AUTOSAR XML (schema 3.1.2)
package /Components/SWC_ThMgt
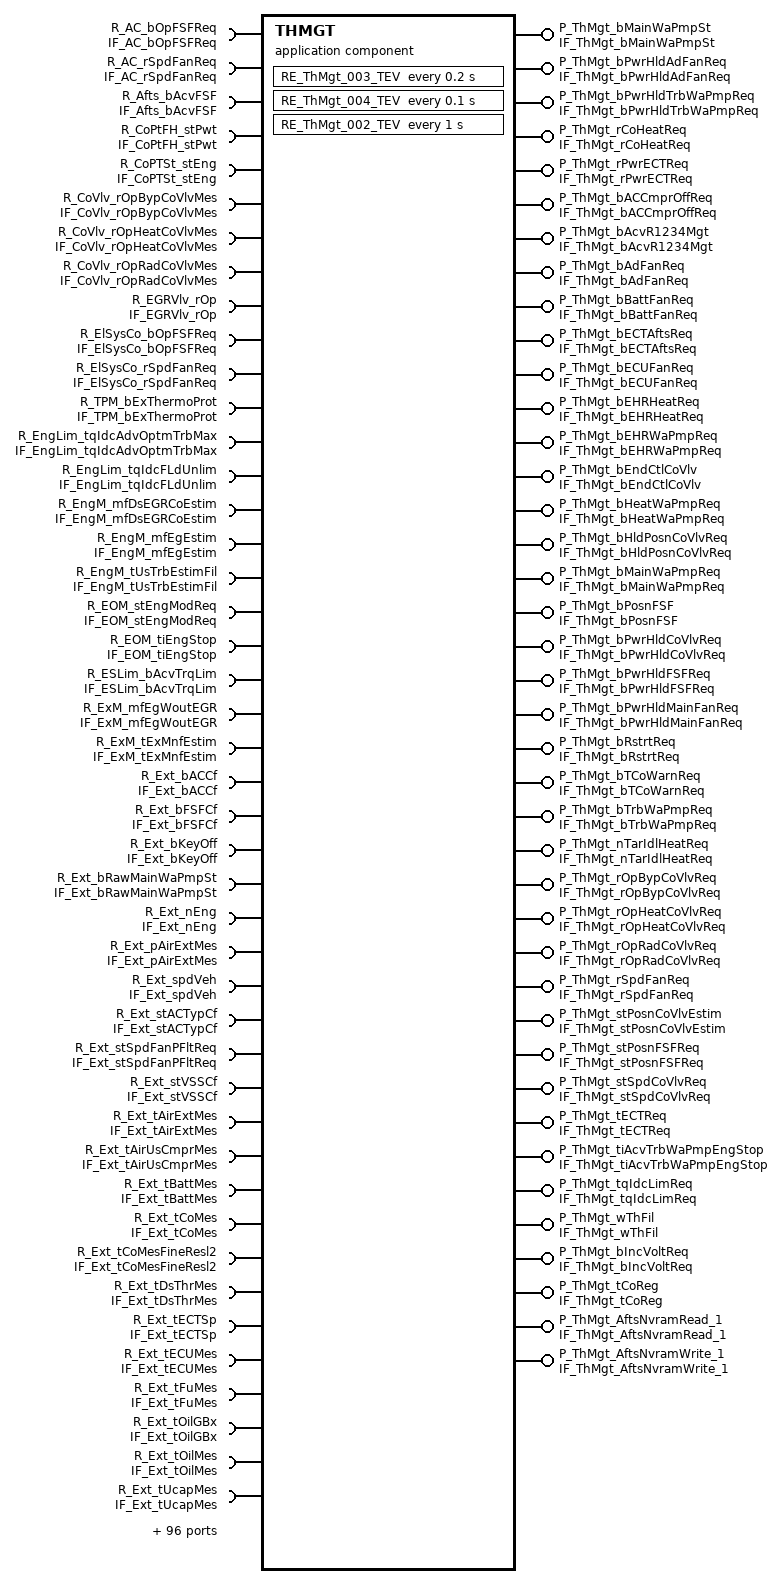
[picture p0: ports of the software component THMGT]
  application software component type THMGT
    125 x require port:
      R_AC_bOpFSFReq: unqueued-receiver-com-spec{data-element=AC_bOpFSFReq, init-value=AC_bOpFSFReq_in, resync-time=0}, required-interface=IF_AC_bOpFSFReq
      R_AC_rSpdFanReq: unqueued-receiver-com-spec{data-element=AC_rSpdFanReq, init-value=AC_rSpdFanReq_in, resync-time=0}, required-interface=IF_AC_rSpdFanReq
      R_Afts_bAcvFSF: unqueued-receiver-com-spec{data-element=Afts_bAcvFSF, init-value=Afts_bAcvFSF_in, resync-time=0}, required-interface=IF_Afts_bAcvFSF
      R_CoPtFH_stPwt: unqueued-receiver-com-spec{data-element=CoPtFH_stPwt, init-value=CoPtFH_stPwt_in, resync-time=0}, required-interface=IF_CoPtFH_stPwt
      R_CoPTSt_stEng: unqueued-receiver-com-spec{data-element=CoPTSt_stEng, init-value=ConstantValue, resync-time=0}, required-interface=IF_CoPTSt_stEng
      R_CoVlv_rOpBypCoVlvMes: unqueued-receiver-com-spec{data-element=CoVlv_rOpBypCoVlvMes, init-value=CoVlv_rOpBypCoVlvMes_in, resync-time=0}, required-interface=IF_CoVlv_rOpBypCoVlvMes
      R_CoVlv_rOpHeatCoVlvMes: unqueued-receiver-com-spec{data-element=CoVlv_rOpHeatCoVlvMes, init-value=CoVlv_rOpHeatCoVlvMes_in, resync-time=0}, required-interface=IF_CoVlv_rOpHeatCoVlvMes
      R_CoVlv_rOpRadCoVlvMes: unqueued-receiver-com-spec{data-element=CoVlv_rOpRadCoVlvMes, init-value=CoVlv_rOpRadCoVlvMes_in, resync-time=0}, required-interface=IF_CoVlv_rOpRadCoVlvMes
      R_EGRVlv_rOp: unqueued-receiver-com-spec{data-element=EGRVlv_rOp, init-value=EGRVlv_rOp_in, resync-time=0}, required-interface=IF_EGRVlv_rOp
      R_ElSysCo_bOpFSFReq: unqueued-receiver-com-spec{data-element=ElSysCo_bOpFSFReq, init-value=ElSysCo_bOpFSFReq_in, resync-time=0}, required-interface=IF_ElSysCo_bOpFSFReq
      R_ElSysCo_rSpdFanReq: unqueued-receiver-com-spec{data-element=ElSysCo_rSpdFanReq, init-value=ElSysCo_rSpdFanReq_in, resync-time=0}, required-interface=IF_ElSysCo_rSpdFanReq
      R_TPM_bExThermoProt: unqueued-receiver-com-spec{data-element=TPM_bExThermoProt, init-value=ConstantValue1, resync-time=0}, required-interface=IF_TPM_bExThermoProt
      R_EngLim_tqIdcAdvOptmTrbMax: unqueued-receiver-com-spec{data-element=EngLim_tqIdcAdvOptmTrbMax, init-value=ConstantValue3, resync-time=0}, required-interface=IF_EngLim_tqIdcAdvOptmTrbMax
      R_EngLim_tqIdcFLdUnlim: unqueued-receiver-com-spec{data-element=EngLim_tqIdcFLdUnlim, init-value=EngLim_tqIdcFLdUnlim_in, resync-time=0}, required-interface=IF_EngLim_tqIdcFLdUnlim
      R_EngM_mfDsEGRCoEstim: unqueued-receiver-com-spec{data-element=EngM_mfDsEGRCoEstim, init-value=EngM_mfDsEGRCoEstim_in, resync-time=0}, required-interface=IF_EngM_mfDsEGRCoEstim
      R_EngM_mfEgEstim: unqueued-receiver-com-spec{data-element=EngM_mfEgEstim, init-value=EngM_mfEgEstim_in, resync-time=0}, required-interface=IF_EngM_mfEgEstim
      R_EngM_tUsTrbEstimFil: unqueued-receiver-com-spec{data-element=EngM_tUsTrbEstimFil, init-value=EngM_tUsTrbEstimFil_in, resync-time=0}, required-interface=IF_EngM_tUsTrbEstimFil
      R_EOM_stEngModReq: unqueued-receiver-com-spec{data-element=EOM_stEngModReq, init-value=EOM_stEngModReq_in, resync-time=0}, required-interface=IF_EOM_stEngModReq
      R_EOM_tiEngStop: unqueued-receiver-com-spec{data-element=EOM_tiEngStop, init-value=ConstantValue5, resync-time=0}, required-interface=IF_EOM_tiEngStop
      R_ESLim_bAcvTrqLim: unqueued-receiver-com-spec{data-element=ESLim_bAcvTrqLim, init-value=ESLim_bAcvTrqLim_in, resync-time=0}, required-interface=IF_ESLim_bAcvTrqLim
      R_ExM_mfEgWoutEGR: unqueued-receiver-com-spec{data-element=ExM_mfEgWoutEGR, init-value=ConstantValue7, resync-time=0}, required-interface=IF_ExM_mfEgWoutEGR
      R_ExM_tExMnfEstim: unqueued-receiver-com-spec{data-element=ExM_tExMnfEstim, init-value=ConstantValue9, resync-time=0}, required-interface=IF_ExM_tExMnfEstim
      R_Ext_bACCf: unqueued-receiver-com-spec{data-element=Ext_bACCf, init-value=Ext_bACCf_in, resync-time=0}, required-interface=IF_Ext_bACCf
      R_Ext_bFSFCf: unqueued-receiver-com-spec{data-element=Ext_bFSFCf, init-value=Ext_bFSFCf_in, resync-time=0}, required-interface=IF_Ext_bFSFCf
      R_Ext_bKeyOff: unqueued-receiver-com-spec{data-element=Ext_bKeyOff, init-value=Ext_bKeyOff_in, resync-time=0}, required-interface=IF_Ext_bKeyOff
      R_Ext_bRawMainWaPmpSt: unqueued-receiver-com-spec{data-element=Ext_bRawMainWaPmpSt, init-value=Ext_bRawMainWaPmpSt_in, resync-time=0}, required-interface=IF_Ext_bRawMainWaPmpSt
      R_Ext_nEng: unqueued-receiver-com-spec{data-element=Ext_nEng, init-value=ConstantValue11, resync-time=0}, required-interface=IF_Ext_nEng
      R_Ext_pAirExtMes: unqueued-receiver-com-spec{data-element=Ext_pAirExtMes, init-value=ConstantValue13, resync-time=0}, required-interface=IF_Ext_pAirExtMes
      R_Ext_spdVeh: unqueued-receiver-com-spec{data-element=Ext_spdVeh, init-value=ConstantValue15, resync-time=0}, required-interface=IF_Ext_spdVeh
      R_Ext_stACTypCf: unqueued-receiver-com-spec{data-element=Ext_stACTypCf, init-value=Ext_stACTypCf_in, resync-time=0}, required-interface=IF_Ext_stACTypCf
      R_Ext_stSpdFanPFltReq: unqueued-receiver-com-spec{data-element=Ext_stSpdFanPFltReq, init-value=Ext_stSpdFanPFltReq_in, resync-time=0}, required-interface=IF_Ext_stSpdFanPFltReq
      R_Ext_stVSSCf: unqueued-receiver-com-spec{data-element=Ext_stVSSCf, init-value=ConstantValue17, resync-time=0}, required-interface=IF_Ext_stVSSCf
      R_Ext_tAirExtMes: unqueued-receiver-com-spec{data-element=Ext_tAirExtMes, init-value=ConstantValue19, resync-time=0}, required-interface=IF_Ext_tAirExtMes
      R_Ext_tAirUsCmprMes: unqueued-receiver-com-spec{data-element=Ext_tAirUsCmprMes, init-value=Ext_tAirUsCmprMes_in, resync-time=0}, required-interface=IF_Ext_tAirUsCmprMes
      R_Ext_tBattMes: unqueued-receiver-com-spec{data-element=Ext_tBattMes, init-value=ConstantValue21, resync-time=0}, required-interface=IF_Ext_tBattMes
      R_Ext_tCoMes: unqueued-receiver-com-spec{data-element=Ext_tCoMes, init-value=ConstantValue23, resync-time=0}, required-interface=IF_Ext_tCoMes
      R_Ext_tCoMesFineResl2: unqueued-receiver-com-spec{data-element=Ext_tCoMesFineResl2, init-value=Ext_tCoMesFineResl2_in, resync-time=0}, required-interface=IF_Ext_tCoMesFineResl2
      R_Ext_tDsThrMes: unqueued-receiver-com-spec{data-element=Ext_tDsThrMes, init-value=ConstantValue25, resync-time=0}, required-interface=IF_Ext_tDsThrMes
      R_Ext_tECTSp: unqueued-receiver-com-spec{data-element=Ext_tECTSp, init-value=Ext_tECTSp_in, resync-time=0}, required-interface=IF_Ext_tECTSp
      R_Ext_tECUMes: unqueued-receiver-com-spec{data-element=Ext_tECUMes, init-value=Ext_tECUMes_in, resync-time=0}, required-interface=IF_Ext_tECUMes
      R_Ext_tFuMes: unqueued-receiver-com-spec{data-element=Ext_tFuMes, init-value=Ext_tFuMes_in, resync-time=0}, required-interface=IF_Ext_tFuMes
      R_Ext_tOilGBx: unqueued-receiver-com-spec{data-element=Ext_tOilGBx, init-value=ConstantValue27, resync-time=0}, required-interface=IF_Ext_tOilGBx
      R_Ext_tOilMes: unqueued-receiver-com-spec{data-element=Ext_tOilMes, init-value=ConstantValue29, resync-time=0}, required-interface=IF_Ext_tOilMes
      R_Ext_tUcapMes: unqueued-receiver-com-spec{data-element=Ext_tUcapMes, init-value=Ext_tUcapMes_in, resync-time=0}, required-interface=IF_Ext_tUcapMes
      R_Ext_tUsPFlt: unqueued-receiver-com-spec{data-element=Ext_tUsPFlt, init-value=Ext_tUsPFlt_in, resync-time=0}, required-interface=IF_Ext_tUsPFlt
      R_Ext_tUsThrMes: unqueued-receiver-com-spec{data-element=Ext_tUsThrMes, init-value=Ext_tUsThrMes_in, resync-time=0}, required-interface=IF_Ext_tUsThrMes
      R_Ext_tVSS: unqueued-receiver-com-spec{data-element=Ext_tVSS, init-value=Ext_tVSS_in, resync-time=0}, required-interface=IF_Ext_tVSS
      R_IgSys_tqIdcEstim: unqueued-receiver-com-spec{data-element=IgSys_tqIdcEstim, init-value=ConstantValue31, resync-time=0}, required-interface=IF_IgSys_tqIdcEstim
      R_PFlt_bPFltRgnReq: unqueued-receiver-com-spec{data-element=PFlt_bPFltRgnReq, init-value=PFlt_bPFltRgnReq_in, resync-time=0}, required-interface=IF_PFlt_bPFltRgnReq
      R_PFlt_bPFltRgnSrvReq: unqueued-receiver-com-spec{data-element=PFlt_bPFltRgnSrvReq, init-value=PFlt_bPFltRgnSrvReq_in, resync-time=0}, required-interface=IF_PFlt_bPFltRgnSrvReq
      R_PhyM_tTrbCaseEstim: unqueued-receiver-com-spec{data-element=PhyM_tTrbCaseEstim, init-value=PhyM_tTrbCaseEstim_in, resync-time=0}, required-interface=IF_PhyM_tTrbCaseEstim
      R_ShdFlap_stPosn: unqueued-receiver-com-spec{data-element=ShdFlap_stPosn, init-value=ShdFlap_stPosn_in, resync-time=0}, required-interface=IF_ShdFlap_stPosn
      R_ShwRm_bAcvFSF: unqueued-receiver-com-spec{data-element=ShwRm_bAcvFSF, init-value=ShwRm_bAcvFSF_in, resync-time=0}, required-interface=IF_ShwRm_bAcvFSF
      R_Stg_agStrWhl: unqueued-receiver-com-spec{data-element=Stg_agStrWhl, init-value=ConstantValue33, resync-time=0}, required-interface=IF_Stg_agStrWhl
      R_Stg_agvStrWhl: unqueued-receiver-com-spec{data-element=Stg_agvStrWhl, init-value=Stg_agvStrWhl_in, resync-time=0}, required-interface=IF_Stg_agvStrWhl
      R_Stg_tSysStrWhl: unqueued-receiver-com-spec{data-element=Stg_tSysStrWhl, init-value=Stg_tSysStrWhl_in, resync-time=0}, required-interface=IF_Stg_tSysStrWhl
      R_TqCmp_bOpFSFReq_tAir: unqueued-receiver-com-spec{data-element=TqCmp_bOpFSFReq_tAir, init-value=TqCmp_bOpFSFReq_tAir_in, resync-time=0}, required-interface=IF_TqCmp_bOpFSFReq_tAir
      R_TqEst_tqIdcEstim: unqueued-receiver-com-spec{data-element=TqEst_tqIdcEstim, init-value=ConstantValue35, resync-time=0}, required-interface=IF_TqEst_tqIdcEstim
      R_Veh_bHeatReq: unqueued-receiver-com-spec{data-element=Veh_bHeatReq, init-value=Veh_bHeatReq_in, resync-time=0}, required-interface=IF_Veh_bHeatReq
      R_Veh_bHeatWaPmpReq: unqueued-receiver-com-spec{data-element=Veh_bHeatWaPmpReq, init-value=Veh_bHeatWaPmpReq_in, resync-time=0}, required-interface=IF_Veh_bHeatWaPmpReq
      R_Veh_stHeatCoFlowReq: unqueued-receiver-com-spec{data-element=Veh_stHeatCoFlowReq, init-value=Veh_stHeatCoFlowReq_in, resync-time=0}, required-interface=IF_Veh_stHeatCoFlowReq
      R_ThMgt_wThFil: unqueued-receiver-com-spec{data-element=ThMgt_wThFil, init-value=ThMgt_wThFil_in, resync-time=0}, required-interface=IF_ThMgt_wThFil
      R_AirSys_rOpEGRCoBypReq: unqueued-receiver-com-spec{data-element=AirSys_rOpEGRCoBypReq, init-value=AirSys_rOpEGRCoBypReq_in, resync-time=0}, required-interface=IF_AirSys_rOpEGRCoBypReq
      R_CoPt_bTqTx: unqueued-receiver-com-spec{data-element=CoPt_bTqTx, init-value=ConstantValue37, resync-time=0}, required-interface=IF_CoPt_bTqTx
      R_CoPt_noEgdGearCord: unqueued-receiver-com-spec{data-element=CoPt_noEgdGearCord, init-value=ConstantValue39, resync-time=0}, required-interface=IF_CoPt_noEgdGearCord
      R_CoPt_rSpdFanReqProtManClu: unqueued-receiver-com-spec{data-element=CoPt_rSpdFanReqProtManClu, init-value=CoPt_rSpdFanReqProtManClu_in, resync-time=0}, required-interface=IF_CoPt_rSpdFanReqProtManClu
      R_CoPt_stCpl: unqueued-receiver-com-spec{data-element=CoPt_stCpl, init-value=ConstantValue41, resync-time=0}, required-interface=IF_CoPt_stCpl
      R_EOM_stCmbTdOff: unqueued-receiver-com-spec{data-element=EOM_stCmbTdOff, init-value=EOM_stCmbTdOff_in, resync-time=0}, required-interface=IF_EOM_stCmbTdOff
      R_Ext_stGBxCf: unqueued-receiver-com-spec{data-element=Ext_stGBxCf, init-value=ConstantValue43, resync-time=0}, required-interface=IF_Ext_stGBxCf
      R_KnkMgt_prm_ctRblInjCutOffPtl: unqueued-receiver-com-spec{data-element=KnkMgt_prm_ctRblInjCutOffPtl, init-value=ArrayConstantValue, resync-time=0}, required-interface=IF_KnkMgt_prm_ctRblInjCutOffPtl
      R_OAM_rOilDil: unqueued-receiver-com-spec{data-element=OAM_rOilDil, init-value=OAM_rOilDil_in, resync-time=0}, required-interface=IF_OAM_rOilDil
      R_RvAltMgt_tRvAltStatEstim: unqueued-receiver-com-spec{data-element=RvAltMgt_tRvAltStatEstim, init-value=ConstantValue45, resync-time=0}, required-interface=IF_RvAltMgt_tRvAltStatEstim
      R_WaTEst_rErrTCo: unqueued-receiver-com-spec{data-element=WaTEst_rErrTCo, init-value=WaTEst_rErrTCo_in, resync-time=0}, required-interface=IF_WaTEst_rErrTCo
      R_WaTEst_tMtlEngEstim: unqueued-receiver-com-spec{data-element=WaTEst_tMtlEngEstim, init-value=WaTEst_tMtlEngEstim_in, resync-time=0}, required-interface=IF_WaTEst_tMtlEngEstim
      R_ThMgt_tCoReg: unqueued-receiver-com-spec{data-element=ThMgt_tCoReg, init-value=ThMgt_tCoReg_in, resync-time=0}, required-interface=IF_ThMgt_tCoReg
      R_IgSys_bAcvLoTCoRegKnk: unqueued-receiver-com-spec{data-element=IgSys_bAcvLoTCoRegKnk, init-value=IgSys_bAcvLoTCoRegKnk_in, resync-time=0}, required-interface=IF_IgSys_bAcvLoTCoRegKnk
      R_InThM_tAirUsInVlvEstim: unqueued-receiver-com-spec{data-element=InThM_tAirUsInVlvEstim, init-value=ConstantValue47, resync-time=0}, required-interface=IF_InThM_tAirUsInVlvEstim
      R_TqSys_tqIdcAirReqGen: unqueued-receiver-com-spec{data-element=TqSys_tqIdcAirReqGen, init-value=ConstantValue49, resync-time=0}, required-interface=IF_TqSys_tqIdcAirReqGen
      R_FRM_bAcvAdFan: required-interface=FunctionInhibition
      R_FRM_bAcvBattFan: required-interface=FunctionInhibition
      R_FRM_bAcvBoilLimChg: required-interface=FunctionInhibition
      R_FRM_bAcvCoVlvMaxOp: required-interface=FunctionInhibition
      R_FRM_bAcvCoVlvOpByp: required-interface=FunctionInhibition
      R_FRM_bAcvCoVlvOpHeat: required-interface=FunctionInhibition
      R_FRM_bAcvCoVlvOpRad: required-interface=FunctionInhibition
      R_FRM_bAcvECUFan: required-interface=FunctionInhibition
      R_FRM_bAcvEHRPmp: required-interface=FunctionInhibition
      R_FRM_bAcvFanHiSpd: required-interface=FunctionInhibition
      R_FRM_bAcvFanHiSpdRcvMod: required-interface=FunctionInhibition
      R_FRM_bAcvFanLoSpd: required-interface=FunctionInhibition
      R_FRM_bAcvHeatWaPmp: required-interface=FunctionInhibition
      R_FRM_bAcvLoTCoReg: required-interface=FunctionInhibition
      R_FRM_bAcvLoThdACCmprOff: required-interface=FunctionInhibition
      R_FRM_bAcvLoThdTCoWarn: required-interface=FunctionInhibition
      R_FRM_bAcvNoEgdGearDft: required-interface=FunctionInhibition
      R_FRM_bAcvOpFSF: required-interface=FunctionInhibition
      R_FRM_bAcvTCoWarn: required-interface=FunctionInhibition
      R_FRM_bAcvThMgtRcvModTAlt: required-interface=FunctionInhibition
      R_FRM_bAcvThMgtRcvModTECU: required-interface=FunctionInhibition
      R_FRM_bAcvThMgtRcvValMfEg: required-interface=FunctionInhibition
      R_FRM_bAcvThMgtRcvValTAirExt: required-interface=FunctionInhibition
      R_FRM_bAcvThMgtRcvValTAirIn: required-interface=FunctionInhibition
      R_FRM_bAcvThMgtRcvValTCAC: required-interface=FunctionInhibition
      R_FRM_bAcvThMgtRcvValTEg: required-interface=FunctionInhibition
      R_FRM_bAcvThMgtRcvValTqIdc: required-interface=FunctionInhibition
      R_FRM_bAcvThMgtRcvValTUsPFlt: required-interface=FunctionInhibition
      R_FRM_bAcvTrbWaPmp: required-interface=FunctionInhibition
      R_FRM_bAcvVeryLoTCoReg: required-interface=FunctionInhibition
      R_FRM_bDeacCoBoilLim: required-interface=FunctionInhibition
      R_FRM_bDeacCoVlv: required-interface=FunctionInhibition
      R_FRM_bDiMoveFSFReq: required-interface=FunctionInhibition
      R_FRM_bInhCTICoHeat: required-interface=FunctionInhibition
      R_FRM_bInhDiagCoBoilLim: required-interface=FunctionInhibition
      R_FRM_bInhDiagFctFSF: required-interface=FunctionInhibition
      R_FRM_bInhDiagTCoWarn: required-interface=FunctionInhibition
      R_FRM_bInhECTPwrLim: required-interface=FunctionInhibition
      R_FRM_bInhEHRPmp: required-interface=FunctionInhibition
      R_FRM_bInhHeatReqMainWaPmp: required-interface=FunctionInhibition
      R_FRM_bInhHeatWaPmp: required-interface=FunctionInhibition
      R_FRM_bInhIdlIncCoHeat: required-interface=FunctionInhibition
      R_FRM_bInhTCoBlockDiag: required-interface=FunctionInhibition
      R_FRM_bInhTCoColdDiag: required-interface=FunctionInhibition
      R_FRM_bInhTCoMdlCompDiag: required-interface=FunctionInhibition
      R_FRM_bInhTCoRiseDiag: required-interface=FunctionInhibition
      R_FRM_bInhThermoDiag1: required-interface=FunctionInhibition
    38 x provide port:
      P_ThMgt_bMainWaPmpSt: unqueued-sender-com-spec{data-element=ThMgt_bMainWaPmpSt, can-invalidate=false, init-value=ThMgt_bMainWaPmpSt_out}, provided-interface=IF_ThMgt_bMainWaPmpSt
      P_ThMgt_bPwrHldAdFanReq: unqueued-sender-com-spec{data-element=ThMgt_bPwrHldAdFanReq, can-invalidate=false, init-value=ThMgt_bPwrHldAdFanReq_out}, provided-interface=IF_ThMgt_bPwrHldAdFanReq
      P_ThMgt_bPwrHldTrbWaPmpReq: unqueued-sender-com-spec{data-element=ThMgt_bPwrHldTrbWaPmpReq, can-invalidate=false, init-value=ThMgt_bPwrHldTrbWaPmpReq_out}, provided-interface=IF_ThMgt_bPwrHldTrbWaPmpReq
      P_ThMgt_rCoHeatReq: unqueued-sender-com-spec{data-element=ThMgt_rCoHeatReq, can-invalidate=false, init-value=ThMgt_rCoHeatReq_out}, provided-interface=IF_ThMgt_rCoHeatReq
      P_ThMgt_rPwrECTReq: unqueued-sender-com-spec{data-element=ThMgt_rPwrECTReq, can-invalidate=false, init-value=ThMgt_rPwrECTReq_out}, provided-interface=IF_ThMgt_rPwrECTReq
      P_ThMgt_bACCmprOffReq: unqueued-sender-com-spec{data-element=ThMgt_bACCmprOffReq, can-invalidate=false, init-value=ConstantValue51}, provided-interface=IF_ThMgt_bACCmprOffReq
      P_ThMgt_bAcvR1234Mgt: unqueued-sender-com-spec{data-element=ThMgt_bAcvR1234Mgt, can-invalidate=false, init-value=ConstantValue53}, provided-interface=IF_ThMgt_bAcvR1234Mgt
      P_ThMgt_bAdFanReq: unqueued-sender-com-spec{data-element=ThMgt_bAdFanReq, can-invalidate=false, init-value=ThMgt_bAdFanReq_out}, provided-interface=IF_ThMgt_bAdFanReq
      P_ThMgt_bBattFanReq: unqueued-sender-com-spec{data-element=ThMgt_bBattFanReq, can-invalidate=false, init-value=ThMgt_bBattFanReq_out}, provided-interface=IF_ThMgt_bBattFanReq
      P_ThMgt_bECTAftsReq: unqueued-sender-com-spec{data-element=ThMgt_bECTAftsReq, can-invalidate=false, init-value=ThMgt_bECTAftsReq_out}, provided-interface=IF_ThMgt_bECTAftsReq
      P_ThMgt_bECUFanReq: unqueued-sender-com-spec{data-element=ThMgt_bECUFanReq, can-invalidate=false, init-value=ThMgt_bECUFanReq_out}, provided-interface=IF_ThMgt_bECUFanReq
      P_ThMgt_bEHRHeatReq: unqueued-sender-com-spec{data-element=ThMgt_bEHRHeatReq, can-invalidate=false, init-value=ThMgt_bEHRHeatReq_out}, provided-interface=IF_ThMgt_bEHRHeatReq
      P_ThMgt_bEHRWaPmpReq: unqueued-sender-com-spec{data-element=ThMgt_bEHRWaPmpReq, can-invalidate=false, init-value=ThMgt_bEHRWaPmpReq_out}, provided-interface=IF_ThMgt_bEHRWaPmpReq
      P_ThMgt_bEndCtlCoVlv: unqueued-sender-com-spec{data-element=ThMgt_bEndCtlCoVlv, can-invalidate=false, init-value=ThMgt_bEndCtlCoVlv_out}, provided-interface=IF_ThMgt_bEndCtlCoVlv
      P_ThMgt_bHeatWaPmpReq: unqueued-sender-com-spec{data-element=ThMgt_bHeatWaPmpReq, can-invalidate=false, init-value=ThMgt_bHeatWaPmpReq_out}, provided-interface=IF_ThMgt_bHeatWaPmpReq
      P_ThMgt_bHldPosnCoVlvReq: unqueued-sender-com-spec{data-element=ThMgt_bHldPosnCoVlvReq, can-invalidate=false, init-value=ThMgt_bHldPosnCoVlvReq_out}, provided-interface=IF_ThMgt_bHldPosnCoVlvReq
      P_ThMgt_bMainWaPmpReq: unqueued-sender-com-spec{data-element=ThMgt_bMainWaPmpReq, can-invalidate=false, init-value=ThMgt_bMainWaPmpReq_out}, provided-interface=IF_ThMgt_bMainWaPmpReq
      P_ThMgt_bPosnFSF: unqueued-sender-com-spec{data-element=ThMgt_bPosnFSF, can-invalidate=false, init-value=ConstantValue55}, provided-interface=IF_ThMgt_bPosnFSF
      P_ThMgt_bPwrHldCoVlvReq: unqueued-sender-com-spec{data-element=ThMgt_bPwrHldCoVlvReq, can-invalidate=false, init-value=ThMgt_bPwrHldCoVlvReq_out}, provided-interface=IF_ThMgt_bPwrHldCoVlvReq
      P_ThMgt_bPwrHldFSFReq: unqueued-sender-com-spec{data-element=ThMgt_bPwrHldFSFReq, can-invalidate=false, init-value=ThMgt_bPwrHldFSFReq_out}, provided-interface=IF_ThMgt_bPwrHldFSFReq
      P_ThMgt_bPwrHldMainFanReq: unqueued-sender-com-spec{data-element=ThMgt_bPwrHldMainFanReq, can-invalidate=false, init-value=ThMgt_bPwrHldMainFanReq_out}, provided-interface=IF_ThMgt_bPwrHldMainFanReq
      P_ThMgt_bRstrtReq: unqueued-sender-com-spec{data-element=ThMgt_bRstrtReq, can-invalidate=false, init-value=ThMgt_bRstrtReq_out}, provided-interface=IF_ThMgt_bRstrtReq
      P_ThMgt_bTCoWarnReq: unqueued-sender-com-spec{data-element=ThMgt_bTCoWarnReq, can-invalidate=false, init-value=ThMgt_bTCoWarnReq_out}, provided-interface=IF_ThMgt_bTCoWarnReq
      P_ThMgt_bTrbWaPmpReq: unqueued-sender-com-spec{data-element=ThMgt_bTrbWaPmpReq, can-invalidate=false, init-value=ThMgt_bTrbWaPmpReq_out}, provided-interface=IF_ThMgt_bTrbWaPmpReq
      P_ThMgt_nTarIdlHeatReq: unqueued-sender-com-spec{data-element=ThMgt_nTarIdlHeatReq, can-invalidate=false, init-value=ThMgt_nTarIdlHeatReq_out}, provided-interface=IF_ThMgt_nTarIdlHeatReq
      P_ThMgt_rOpBypCoVlvReq: unqueued-sender-com-spec{data-element=ThMgt_rOpBypCoVlvReq, can-invalidate=false, init-value=ThMgt_rOpBypCoVlvReq_out}, provided-interface=IF_ThMgt_rOpBypCoVlvReq
      P_ThMgt_rOpHeatCoVlvReq: unqueued-sender-com-spec{data-element=ThMgt_rOpHeatCoVlvReq, can-invalidate=false, init-value=ThMgt_rOpHeatCoVlvReq_out}, provided-interface=IF_ThMgt_rOpHeatCoVlvReq
      P_ThMgt_rOpRadCoVlvReq: unqueued-sender-com-spec{data-element=ThMgt_rOpRadCoVlvReq, can-invalidate=false, init-value=ThMgt_rOpRadCoVlvReq_out}, provided-interface=IF_ThMgt_rOpRadCoVlvReq
      P_ThMgt_rSpdFanReq: unqueued-sender-com-spec{data-element=ThMgt_rSpdFanReq, can-invalidate=false, init-value=ThMgt_rSpdFanReq_out}, provided-interface=IF_ThMgt_rSpdFanReq
      P_ThMgt_stPosnCoVlvEstim: unqueued-sender-com-spec{data-element=ThMgt_stPosnCoVlvEstim, can-invalidate=false, init-value=ThMgt_stPosnCoVlvEstim_out}, provided-interface=IF_ThMgt_stPosnCoVlvEstim
      P_ThMgt_stPosnFSFReq: unqueued-sender-com-spec{data-element=ThMgt_stPosnFSFReq, can-invalidate=false, init-value=ThMgt_stPosnFSFReq_out}, provided-interface=IF_ThMgt_stPosnFSFReq
      P_ThMgt_stSpdCoVlvReq: unqueued-sender-com-spec{data-element=ThMgt_stSpdCoVlvReq, can-invalidate=false, init-value=ThMgt_stSpdCoVlvReq_out}, provided-interface=IF_ThMgt_stSpdCoVlvReq
      P_ThMgt_tECTReq: unqueued-sender-com-spec{data-element=ThMgt_tECTReq, can-invalidate=false, init-value=ThMgt_tECTReq_out}, provided-interface=IF_ThMgt_tECTReq
      P_ThMgt_tiAcvTrbWaPmpEngStop: unqueued-sender-com-spec{data-element=ThMgt_tiAcvTrbWaPmpEngStop, can-invalidate=false, init-value=ThMgt_tiAcvTrbWaPmpEngStop_out}, provided-interface=IF_ThMgt_tiAcvTrbWaPmpEngStop
      P_ThMgt_tqIdcLimReq: unqueued-sender-com-spec{data-element=ThMgt_tqIdcLimReq, can-invalidate=false, init-value=ConstantValue57}, provided-interface=IF_ThMgt_tqIdcLimReq
      P_ThMgt_wThFil: unqueued-sender-com-spec{data-element=ThMgt_wThFil, can-invalidate=false, init-value=ThMgt_wThFil_out}, provided-interface=IF_ThMgt_wThFil
      P_ThMgt_bIncVoltReq: unqueued-sender-com-spec{data-element=ThMgt_bIncVoltReq, can-invalidate=false, init-value=ThMgt_bIncVoltReq_out}, provided-interface=IF_ThMgt_bIncVoltReq
      P_ThMgt_tCoReg: unqueued-sender-com-spec{data-element=ThMgt_tCoReg, can-invalidate=false, init-value=ThMgt_tCoReg_out}, provided-interface=IF_ThMgt_tCoReg
    13 x require port:
      R_ThMgt_AntiBoil: required-interface=DiagnosticMonitor
      R_ThMgt_CoSysDfct: required-interface=DiagnosticMonitor
      R_ThMgt_FSFBlockCls: required-interface=DiagnosticMonitor
      R_ThMgt_FSFBlockOp: required-interface=DiagnosticMonitor
      R_ThMgt_TCoBlock: required-interface=DiagnosticMonitor
      R_ThMgt_TCoOverEstim: required-interface=DiagnosticMonitor
      R_ThMgt_TCoSlowRise: required-interface=DiagnosticMonitor
      R_ThMgt_TCoUndEstim: required-interface=DiagnosticMonitor
      R_ThMgt_TCoWarn: required-interface=DiagnosticMonitor
      R_ThMgt_ThermoStuckCls: required-interface=DiagnosticMonitor
      R_ThMgt_ThermoStuckOp: required-interface=DiagnosticMonitor
      R_UCE_stWkuMainRelSt: required-interface=IF_UCE_stWkuMainRelSt
      R_EcuM_CurrentMode: required-interface=EcuM_CurrentMode
    provide port P_ThMgt_AftsNvramRead_1: server-com-spec{operation=op_ThMgt_AftsNvramRead_1, queue-length=1}, provided-interface=IF_ThMgt_AftsNvramRead_1
    provide port P_ThMgt_AftsNvramWrite_1: server-com-spec{operation=op_ThMgt_AftsNvramWrite_1, queue-length=1}, provided-interface=IF_ThMgt_AftsNvramWrite_1
    require port R_EngLim_tqIdcEngCur: unqueued-receiver-com-spec{data-element=EngLim_tqIdcEngCur, init-value=ConstantValue59, resync-time=0}, required-interface=IF_EngLim_tqIdcEngCur
    require port R_TqRes_tqMaxRes: unqueued-receiver-com-spec{data-element=TqRes_tqMaxRes, init-value=ConstantValue61, resync-time=0}, required-interface=IF_TqRes_tqMaxRes
  213 x constant specification:
    AC_bOpFSFReq_in
      value:
        boolean literal AC_bOpFSFReq_in: type=DT_AC_bOpFSFReq, value=false
    AC_rSpdFanReq_in
      value:
        integer literal AC_rSpdFanReq_in: type=DT_AC_rSpdFanReq, value=0
    Afts_bAcvFSF_in
      value:
        boolean literal Afts_bAcvFSF_in: type=DT_Afts_bAcvFSF, value=false
    AirSys_rOpEGRCoBypReq_in
      value:
        integer literal AirSys_rOpEGRCoBypReq_in: type=DT_AirSys_rOpEGRCoBypReq, value=0
    AirSysByp_rOpEGRCoBypReq_Cst
      value:
        integer literal AirSysByp_rOpEGRCoBypReq_Cst: type=DT_AirSysByp_rOpEGRCoBypReq, value=0
    AntiBoil_bRatCorPwrFilIniDly_Cst
      value:
        boolean literal AntiBoil_bRatCorPwrFilIniDly_Cst: type=DT_AntiBoil_bRatCorPwrFilIniDly, value=false
    AntiBoil_rCorPwrFil_Cst
      value:
        integer literal AntiBoil_rCorPwrFil_Cst: type=DT_AntiBoil_rCorPwrFil, value=0
    AntiBoil_tCoMesFil_Cst
      value:
        integer literal AntiBoil_tCoMesFil_Cst: type=DT_AntiBoil_tCoMesFil, value=0
    AntiBoil_tECTReqDly_Cst
      value:
        integer literal AntiBoil_tECTReqDly_Cst: type=DT_AntiBoil_tECTReqDly, value=0
    ArrayConstantValue
      value:
        array specification ArrayConstantValue: type=rt_Array_UInt8_6_m4
          6 x integer literal, all with type=DT_KnkMgt_prm_ctRblInjCutOffPtl, value=0:
            Const
            Const{1..5}
    AtyModMgt_bLoTCoRegReq_Cst
      value:
        boolean literal AtyModMgt_bLoTCoRegReq_Cst: type=DT_AtyModMgt_bLoTCoRegReq, value=false
    AtyModMgt_tECTReq_Cst
      value:
        integer literal AtyModMgt_tECTReq_Cst: type=DT_AtyModMgt_tECTReq, value=0
    CmptFil_agStrWhlFil_Cst
      value:
        integer literal CmptFil_agStrWhlFil_Cst: type=DT_CmptFil_agStrWhlFil, value=0
    CmptFil_agvStrWhlFil_Cst
      value:
        integer literal CmptFil_agvStrWhlFil_Cst: type=DT_CmptFil_agvStrWhlFil, value=0
    CmptFil_tCACFil_Cst
      value:
        integer literal CmptFil_tCACFil_Cst: type=DT_CmptFil_tCACFil, value=0
    CoAftsMgt_tECTAftsReq_Cst
      value:
        integer literal CoAftsMgt_tECTAftsReq_Cst: type=DT_CoAftsMgt_tECTAftsReq, value=0
    ConstantValue
      value:
        integer literal ConstantValue: type=DT_CoPTSt_stEng, value=1
    ConstantValue1
      value:
        boolean literal ConstantValue1: type=DT_TPM_bExThermoProt, value=false
    ConstantValue11
      value:
        integer literal ConstantValue11: type=DT_Ext_nEng, value=0
    ConstantValue13
      value:
        integer literal ConstantValue13: type=DT_Ext_pAirExtMes, value=500
    ConstantValue15
      value:
        integer literal ConstantValue15: type=DT_Ext_spdVeh, value=0
    ConstantValue17
      value:
        integer literal ConstantValue17: type=DT_Ext_stVSSCf, value=0
    ConstantValue19
      value:
        integer literal ConstantValue19: type=DT_Ext_tAirExtMes, value=20
    ConstantValue2
      value:
        integer literal ConstantValue2: type=DT_PwtFil_tCoRegFil3, value=0
    ConstantValue21
      value:
        integer literal ConstantValue21: type=DT_Ext_tBattMes, value=-60
    ConstantValue23
      value:
        integer literal ConstantValue23: type=DT_Ext_tCoMes, value=20
    ConstantValue25
      value:
        integer literal ConstantValue25: type=DT_Ext_tDsThrMes, value=25
    ConstantValue27
      value:
        integer literal ConstantValue27: type=DT_Ext_tOilGBx, value=0
    ConstantValue29
      value:
        integer literal ConstantValue29: type=DT_Ext_tOilMes, value=0
    ConstantValue3
      value:
        integer literal ConstantValue3: type=DT_EngLim_tqIdcAdvOptmTrbMax, value=0
    ConstantValue31
      value:
        integer literal ConstantValue31: type=DT_IgSys_tqIdcEstim, value=0
    ConstantValue33
      value:
        integer literal ConstantValue33: type=DT_Stg_agStrWhl, value=-7800
    ConstantValue35
      value:
        integer literal ConstantValue35: type=DT_TqEst_tqIdcEstim, value=0
    ConstantValue37
      value:
        boolean literal ConstantValue37: type=DT_CoPt_bTqTx, value=false
    ConstantValue39
      value:
        integer literal ConstantValue39: type=DT_CoPt_noEgdGearCord, value=0
    ConstantValue41
      value:
        integer literal ConstantValue41: type=DT_CoPt_stCpl, value=0
    ConstantValue43
      value:
        integer literal ConstantValue43: type=DT_Ext_stGBxCf, value=0
    ConstantValue45
      value:
        integer literal ConstantValue45: type=DT_RvAltMgt_tRvAltStatEstim, value=-15
    ConstantValue47
      value:
        integer literal ConstantValue47: type=DT_InThM_tAirUsInVlvEstim, value=0
    ConstantValue49
      value:
        integer literal ConstantValue49: type=DT_TqSys_tqIdcAirReqGen, value=0
    ConstantValue5
      value:
        integer literal ConstantValue5: type=DT_EOM_tiEngStop, value=864000
    ConstantValue51
      value:
        boolean literal ConstantValue51: type=DT_ThMgt_bACCmprOffReq, value=false
    ConstantValue53
      value:
        boolean literal ConstantValue53: type=DT_ThMgt_bAcvR1234Mgt, value=false
    ConstantValue55
      value:
        boolean literal ConstantValue55: type=DT_ThMgt_bPosnFSF, value=false
    ConstantValue57
      value:
        integer literal ConstantValue57: type=DT_ThMgt_tqIdcLimReq, value=0
    ConstantValue59
      value:
        integer literal ConstantValue59: type=DT_EngLim_tqIdcEngCur, value=0
    ConstantValue61
      value:
        integer literal ConstantValue61: type=DT_TqRes_tqMaxRes, value=0
    ConstantValue7
      value:
        integer literal ConstantValue7: type=DT_ExM_mfEgWoutEGR, value=0
    ConstantValue9
      value:
        integer literal ConstantValue9: type=DT_ExM_tExMnfEstim, value=4800
    CoPt_rSpdFanReqProtManClu_in
      value:
        integer literal CoPt_rSpdFanReqProtManClu_in: type=DT_CoPt_rSpdFanReqProtManClu, value=0
    CoPtByp_bTqTx_Cst
      value:
        boolean literal CoPtByp_bTqTx_Cst: type=DT_CoPtByp_bTqTx, value=false
    CoPtByp_noEgdGearCord_Cst
      value:
        integer literal CoPtByp_noEgdGearCord_Cst: type=DT_CoPtByp_noEgdGearCord, value=0
    CoPtByp_stCpl_Cst
      value:
        integer literal CoPtByp_stCpl_Cst: type=DT_CoPtByp_stCpl, value=0
    CoPtFH_stPwt_in
      value:
        integer literal CoPtFH_stPwt_in: type=DT_CoPtFH_stPwt, value=0
    CoVlv_rOpBypCoVlvMes_in
      value:
        integer literal CoVlv_rOpBypCoVlvMes_in: type=DT_CoVlv_rOpBypCoVlvMes, value=0
    CoVlv_rOpHeatCoVlvMes_in
      value:
        integer literal CoVlv_rOpHeatCoVlvMes_in: type=DT_CoVlv_rOpHeatCoVlvMes, value=0
    CoVlv_rOpRadCoVlvMes_in
      value:
        integer literal CoVlv_rOpRadCoVlvMes_in: type=DT_CoVlv_rOpRadCoVlvMes, value=0
    CoVlvCtl_bRstStopHldDly_Cst
      value:
        boolean literal CoVlvCtl_bRstStopHldDly_Cst: type=DT_CoVlvCtl_bRstStopHldDly, value=false
    EGRCo_bOpCoVlvReq_Cst
      value:
        boolean literal EGRCo_bOpCoVlvReq_Cst: type=DT_EGRCo_bOpCoVlvReq, value=false
    EGRCo_stSpdCoVlvReq_Cst
      value:
        integer literal EGRCo_stSpdCoVlvReq_Cst: type=DT_EGRCo_stSpdCoVlvReq, value=0
    EGRVlv_rOp_in
      value:
        integer literal EGRVlv_rOp_in: type=DT_EGRVlv_rOp, value=0
    EGRVlvByp_rOp_Cst
      value:
        integer literal EGRVlvByp_rOp_Cst: type=DT_EGRVlvByp_rOp, value=0
    ElSysCo_bOpFSFReq_in
      value:
        boolean literal ElSysCo_bOpFSFReq_in: type=DT_ElSysCo_bOpFSFReq, value=false
    ElSysCo_rSpdFanReq_in
      value:
        integer literal ElSysCo_rSpdFanReq_in: type=DT_ElSysCo_rSpdFanReq, value=0
    EngLim_tqIdcFLdUnlim_in
      value:
        integer literal EngLim_tqIdcFLdUnlim_in: type=DT_EngLim_tqIdcFLdUnlim, value=0
    EngLimByp_tqIdcEngCur
      value:
        integer literal EngLimByp_tqIdcEngCur: type=DT_EngLimByp_tqIdcEngCur, value=0
    EngM_mfDsEGRCoEstim_in
      value:
        integer literal EngM_mfDsEGRCoEstim_in: type=DT_EngM_mfDsEGRCoEstim, value=0
    EngM_mfEgEstim_in
      value:
        integer literal EngM_mfEgEstim_in: type=DT_EngM_mfEgEstim, value=0
    EngM_tUsTrbEstimFil_in
      value:
        integer literal EngM_tUsTrbEstimFil_in: type=DT_EngM_tUsTrbEstimFil, value=0
    EngMByp_mfDsEGRCoEstim_Cst
      value:
        integer literal EngMByp_mfDsEGRCoEstim_Cst: type=DT_EngMByp_mfDsEGRCoEstim, value=0
    EngMByp_mfEgEstim_Cst
      value:
        integer literal EngMByp_mfEgEstim_Cst: type=DT_EngMByp_mfEgEstim, value=0
    EOM_stCmbTdOff_in
      value:
        integer literal EOM_stCmbTdOff_in: type=DT_EOM_stCmbTdOff, value=15
    EOM_stEngModReq_in
      value:
        integer literal EOM_stEngModReq_in: type=DT_EOM_stEngModReq, value=1
    EOMByp_stCmbTdOff_Cst
      value:
        integer literal EOMByp_stCmbTdOff_Cst: type=DT_EOMByp_stCmbTdOff, value=15
    EOMByp_tiEngStop_Cst
      value:
        integer literal EOMByp_tiEngStop_Cst: type=DT_EOMByp_tiEngStop, value=0
    ESLim_bAcvTrqLim_in
      value:
        boolean literal ESLim_bAcvTrqLim_in: type=DT_ESLim_bAcvTrqLim, value=false
    ESLimByp_bAcvTrqLim_Cst
      value:
        boolean literal ESLimByp_bAcvTrqLim_Cst: type=DT_ESLimByp_bAcvTrqLim, value=false
    Ext_bACCf_in
      value:
        boolean literal Ext_bACCf_in: type=DT_Ext_bACCf, value=false
    Ext_bFSFCf_in
      value:
        boolean literal Ext_bFSFCf_in: type=DT_Ext_bFSFCf, value=false
    Ext_bKeyOff_in
      value:
        boolean literal Ext_bKeyOff_in: type=DT_Ext_bKeyOff, value=false
    Ext_bRawMainWaPmpSt_in
      value:
        boolean literal Ext_bRawMainWaPmpSt_in: type=DT_Ext_bRawMainWaPmpSt, value=true
    Ext_stACTypCf_in
      value:
        integer literal Ext_stACTypCf_in: type=DT_Ext_stACTypCf, value=0
    Ext_stSpdFanPFltReq_in
      value:
        integer literal Ext_stSpdFanPFltReq_in: type=DT_Ext_stSpdFanPFltReq, value=0
    Ext_tAirUsCmprMes_in
      value:
        integer literal Ext_tAirUsCmprMes_in: type=DT_Ext_tAirUsCmprMes, value=20
    Ext_tCoMesFineResl2_in
      value:
        integer literal Ext_tCoMesFineResl2_in: type=DT_Ext_tCoMesFineResl2, value=-500
    Ext_tECTSp_in
      value:
        integer literal Ext_tECTSp_in: type=DT_Ext_tECTSp, value=0
    Ext_tECUMes_in
      value:
        integer literal Ext_tECUMes_in: type=DT_Ext_tECUMes, value=0
    Ext_tFuMes_in
      value:
        integer literal Ext_tFuMes_in: type=DT_Ext_tFuMes, value=20
    Ext_tUcapMes_in
      value:
        integer literal Ext_tUcapMes_in: type=DT_Ext_tUcapMes, value=40
    Ext_tUsPFlt_in
      value:
        integer literal Ext_tUsPFlt_in: type=DT_Ext_tUsPFlt, value=0
    Ext_tUsThrMes_in
      value:
        integer literal Ext_tUsThrMes_in: type=DT_Ext_tUsThrMes, value=25
    Ext_tVSS_in
      value:
        integer literal Ext_tVSS_in: type=DT_Ext_tVSS, value=0
    ExtByp_bFSFCf_Cst
      value:
        boolean literal ExtByp_bFSFCf_Cst: type=DT_ExtByp_bFSFCf, value=false
    ExtByp_bKeyOff_Cst
      value:
        boolean literal ExtByp_bKeyOff_Cst: type=DT_ExtByp_bKeyOff, value=false
    ExtByp_nEng_Cst
      value:
        integer literal ExtByp_nEng_Cst: type=DT_ExtByp_nEng, value=0
    ExtByp_pAirExtMes_Cst
      value:
        integer literal ExtByp_pAirExtMes_Cst: type=DT_ExtByp_pAirExtMes, value=1000
    ExtByp_spdVeh_Cst
      value:
        integer literal ExtByp_spdVeh_Cst: type=DT_ExtByp_spdVeh, value=0
    ExtByp_stGBxCf_Cst
      value:
        integer literal ExtByp_stGBxCf_Cst: type=DT_ExtByp_stGBxCf, value=0
    ExtByp_stVSSCf_Cst
      value:
        integer literal ExtByp_stVSSCf_Cst: type=DT_ExtByp_stVSSCf, value=0
    ExtByp_tAirExtMes_Cst
      value:
        integer literal ExtByp_tAirExtMes_Cst: type=DT_ExtByp_tAirExtMes, value=0
    ExtByp_tAirUsCmprMes_Cst
      value:
        integer literal ExtByp_tAirUsCmprMes_Cst: type=DT_ExtByp_tAirUsCmprMes, value=0
    ExtByp_tCoMes_Cst
      value:
        integer literal ExtByp_tCoMes_Cst: type=DT_ExtByp_tCoMes, value=0
    ExtByp_tCoMesFineResl2_Cst
      value:
        integer literal ExtByp_tCoMesFineResl2_Cst: type=DT_ExtByp_tCoMesFineResl2, value=0
    ExtByp_tDsThrMes_Cst
      value:
        integer literal ExtByp_tDsThrMes_Cst: type=DT_ExtByp_tDsThrMes, value=0
    ExtByp_tECTSp_Cst
      value:
        integer literal ExtByp_tECTSp_Cst: type=DT_ExtByp_tECTSp, value=0
    ExtByp_tFuMes_Cst
      value:
        integer literal ExtByp_tFuMes_Cst: type=DT_ExtByp_tFuMes, value=0
    ExtByp_tOilMes_Cst
      value:
        integer literal ExtByp_tOilMes_Cst: type=DT_ExtByp_tOilMes, value=0
    ExtByp_tUsPFlt_Cst
      value:
        integer literal ExtByp_tUsPFlt_Cst: type=DT_ExtByp_tUsPFlt, value=0
    ExtByp_tUsThrMes_Cst
      value:
        integer literal ExtByp_tUsThrMes_Cst: type=DT_ExtByp_tUsThrMes, value=0
    FRMByp_bAcvBoilLimChg_Cst
      value:
        boolean literal FRMByp_bAcvBoilLimChg_Cst: type=DT_FRMByp_bAcvBoilLimChg, value=false
    FRMByp_bAcvLoTCoReg_Cst
      value:
        boolean literal FRMByp_bAcvLoTCoReg_Cst: type=DT_FRMByp_bAcvLoTCoReg, value=false
    FRMByp_bAcvNoEgdGearDft_Cst
      value:
        boolean literal FRMByp_bAcvNoEgdGearDft_Cst: type=DT_FRMByp_bAcvNoEgdGearDft, value=false
    FRMByp_bAcvTrbWaPmp_Cst
      value:
        boolean literal FRMByp_bAcvTrbWaPmp_Cst: type=DT_FRMByp_bAcvTrbWaPmp, value=false
    FRMByp_bAcvVeryLoTCoReg_Cst
      value:
        boolean literal FRMByp_bAcvVeryLoTCoReg_Cst: type=DT_FRMByp_bAcvVeryLoTCoReg, value=false
    FRMByp_bDeacCoBoilLim_Cst
      value:
        boolean literal FRMByp_bDeacCoBoilLim_Cst: type=DT_FRMByp_bDeacCoBoilLim, value=false
    FRMByp_bInhDiagCoBoilLim_Cst
      value:
        boolean literal FRMByp_bInhDiagCoBoilLim_Cst: type=DT_FRMByp_bInhDiagCoBoilLim, value=false
    FRMByp_bInhTCoColdDiag_Cst
      value:
        boolean literal FRMByp_bInhTCoColdDiag_Cst: type=DT_FRMByp_bInhTCoColdDiag, value=false
    GBxCo_tECTReqDly_Cst
      value:
        integer literal GBxCo_tECTReqDly_Cst: type=DT_GBxCo_tECTReqDly, value=0
    IgSys_bAcvLoTCoRegKnk_in
      value:
        boolean literal IgSys_bAcvLoTCoRegKnk_in: type=DT_IgSys_bAcvLoTCoRegKnk, value=false
    IgSysByp_bAcvLoTCoRegKnk_Cst
      value:
        boolean literal IgSysByp_bAcvLoTCoRegKnk_Cst: type=DT_IgSysByp_bAcvLoTCoRegKnk, value=false
    InpClc_bACCf_Cst
      value:
        boolean literal InpClc_bACCf_Cst: type=DT_InpClc_bACCf, value=false
    InpClc_bEngRun_Cst
      value:
        boolean literal InpClc_bEngRun_Cst: type=DT_InpClc_bEngRun, value=false
    InpClc_bEngStop_Cst
      value:
        boolean literal InpClc_bEngStop_Cst: type=DT_InpClc_bEngStop, value=false
    InpClc_bPFltRgnReq_Cst
      value:
        boolean literal InpClc_bPFltRgnReq_Cst: type=DT_InpClc_bPFltRgnReq, value=false
    InpClc_bPwtRun_Cst
      value:
        boolean literal InpClc_bPwtRun_Cst: type=DT_InpClc_bPwtRun, value=false
    InpClc_tAirInMes_Cst
      value:
        integer literal InpClc_tAirInMes_Cst: type=DT_InpClc_tAirInMes, value=0
    InpClc_tCAC_Cst
      value:
        integer literal InpClc_tCAC_Cst: type=DT_InpClc_tCAC, value=0
    InpClc_tEg_Cst
      value:
        integer literal InpClc_tEg_Cst: type=DT_InpClc_tEg, value=0
    InpClc_tqIdcEstim_Cst
      value:
        integer literal InpClc_tqIdcEstim_Cst: type=DT_InpClc_tqIdcEstim, value=0
    InpClc_tqIdcFld_Cst
      value:
        integer literal InpClc_tqIdcFld_Cst: type=DT_InpClc_tqIdcFld, value=0
    InThMByp_tAirUsInVlvEstim_Cst
      value:
        integer literal InThMByp_tAirUsInVlvEstim_Cst: type=DT_InThMByp_tAirUsInVlvEstim, value=0
    KnkMgtByp_ctRblInjCutOffPtl_Cst
      value:
        integer literal KnkMgtByp_ctRblInjCutOffPtl_Cst: type=DT_KnkMgtByp_ctRblInjCutOffPtl, value=0
    KnkProt_tECTAdpReq_Cst
      value:
        integer literal KnkProt_tECTAdpReq_Cst: type=DT_KnkProt_tECTAdpReq, value=0
    KnkProt_tECTTAirReq_Cst
      value:
        integer literal KnkProt_tECTTAirReq_Cst: type=DT_KnkProt_tECTTAirReq, value=0
    OAM_rOilDil_in
      value:
        integer literal OAM_rOilDil_in: type=DT_OAM_rOilDil, value=0
    OAMByp_rOilDil_Cst
      value:
        integer literal OAMByp_rOilDil_Cst: type=DT_OAMByp_rOilDil, value=0
    OilDilProt_bLoTCoRegReq_Cst
      value:
        boolean literal OilDilProt_bLoTCoRegReq_Cst: type=DT_OilDilProt_bLoTCoRegReq, value=false
    PFlt_bPFltRgnReq_in
      value:
        boolean literal PFlt_bPFltRgnReq_in: type=DT_PFlt_bPFltRgnReq, value=false
    PFlt_bPFltRgnSrvReq_in
      value:
        boolean literal PFlt_bPFltRgnSrvReq_in: type=DT_PFlt_bPFltRgnSrvReq, value=false
    PFltByp_bPFltRgnSrvReq_Cst
      value:
        boolean literal PFltByp_bPFltRgnSrvReq_Cst: type=DT_PFltByp_bPFltRgnSrvReq, value=false
    PhyM_tTrbCaseEstim_in
      value:
        integer literal PhyM_tTrbCaseEstim_in: type=DT_PhyM_tTrbCaseEstim, value=25
    PwtFil_nEngFil_Cst
      value:
        integer literal PwtFil_nEngFil_Cst: type=DT_PwtFil_nEngFil, value=0
    PwtFil_tCoRegFil1_Cst
      value:
        integer literal PwtFil_tCoRegFil1_Cst: type=DT_PwtFil_tCoRegFil1, value=0
    PwtFil_tCoRegFil2_Cst
      value:
        integer literal PwtFil_tCoRegFil2_Cst: type=DT_PwtFil_tCoRegFil2, value=0
    PwtFil_tqIdcEstimFil_Cst
      value:
        integer literal PwtFil_tqIdcEstimFil_Cst: type=DT_PwtFil_tqIdcEstimFil, value=0
    ShdFlap_stPosn_in
      value:
        integer literal ShdFlap_stPosn_in: type=DT_ShdFlap_stPosn, value=0
    ShwRm_bAcvFSF_in
      value:
        boolean literal ShwRm_bAcvFSF_in: type=DT_ShwRm_bAcvFSF, value=false
    Stg_agvStrWhl_in
      value:
        integer literal Stg_agvStrWhl_in: type=DT_Stg_agvStrWhl, value=0
    Stg_tSysStrWhl_in
      value:
        integer literal Stg_tSysStrWhl_in: type=DT_Stg_tSysStrWhl, value=0
    StgByp_agStrWhl_Cst
      value:
        integer literal StgByp_agStrWhl_Cst: type=DT_StgByp_agStrWhl, value=0
    StgByp_agvStrWhl_Cst
      value:
        integer literal StgByp_agvStrWhl_Cst: type=DT_StgByp_agvStrWhl, value=0
    ThEClc_wThFil2_Cst
      value:
        integer literal ThEClc_wThFil2_Cst: type=DT_ThEClc_wThFil2, value=0
    ThMgt_bAdFanReq_out
      value:
        boolean literal ThMgt_bAdFanReq_out: type=DT_ThMgt_bAdFanReq, value=false
    ThMgt_bBattFanReq_out
      value:
        boolean literal ThMgt_bBattFanReq_out: type=DT_ThMgt_bBattFanReq, value=false
    ThMgt_bECTAftsReq_out
      value:
        boolean literal ThMgt_bECTAftsReq_out: type=DT_ThMgt_bECTAftsReq, value=false
    ThMgt_bECUFanReq_out
      value:
        boolean literal ThMgt_bECUFanReq_out: type=DT_ThMgt_bECUFanReq, value=false
    ThMgt_bEHRHeatReq_out
      value:
        boolean literal ThMgt_bEHRHeatReq_out: type=DT_ThMgt_bEHRHeatReq, value=false
    ThMgt_bEHRWaPmpReq_out
      value:
        boolean literal ThMgt_bEHRWaPmpReq_out: type=DT_ThMgt_bEHRWaPmpReq, value=false
    ThMgt_bEndCtlCoVlv_out
      value:
        boolean literal ThMgt_bEndCtlCoVlv_out: type=DT_ThMgt_bEndCtlCoVlv, value=false
    ThMgt_bHeatWaPmpReq_out
      value:
        boolean literal ThMgt_bHeatWaPmpReq_out: type=DT_ThMgt_bHeatWaPmpReq, value=false
    ThMgt_bHldPosnCoVlvReq_out
      value:
        boolean literal ThMgt_bHldPosnCoVlvReq_out: type=DT_ThMgt_bHldPosnCoVlvReq, value=true
    ThMgt_bIncVoltReq_out
      value:
        boolean literal ThMgt_bIncVoltReq_out: type=DT_ThMgt_bIncVoltReq, value=false
    ThMgt_bMainWaPmpReq_out
      value:
        boolean literal ThMgt_bMainWaPmpReq_out: type=DT_ThMgt_bMainWaPmpReq, value=false
    ThMgt_bMainWaPmpSt_out
      value:
        boolean literal ThMgt_bMainWaPmpSt_out: type=DT_ThMgt_bMainWaPmpSt, value=false
    ThMgt_bPwrHldAdFanReq_out
      value:
        boolean literal ThMgt_bPwrHldAdFanReq_out: type=DT_ThMgt_bPwrHldAdFanReq, value=false
    ThMgt_bPwrHldCoVlvReq_out
      value:
        boolean literal ThMgt_bPwrHldCoVlvReq_out: type=DT_ThMgt_bPwrHldCoVlvReq, value=false
    ThMgt_bPwrHldFSFReq_out
      value:
        boolean literal ThMgt_bPwrHldFSFReq_out: type=DT_ThMgt_bPwrHldFSFReq, value=false
    ThMgt_bPwrHldMainFanReq_out
      value:
        boolean literal ThMgt_bPwrHldMainFanReq_out: type=DT_ThMgt_bPwrHldMainFanReq, value=false
    ThMgt_bPwrHldTrbWaPmpReq_out
      value:
        boolean literal ThMgt_bPwrHldTrbWaPmpReq_out: type=DT_ThMgt_bPwrHldTrbWaPmpReq, value=false
    ThMgt_bRstrtReq_out
      value:
        boolean literal ThMgt_bRstrtReq_out: type=DT_ThMgt_bRstrtReq, value=false
    ThMgt_bTCoWarnReq_out
      value:
        boolean literal ThMgt_bTCoWarnReq_out: type=DT_ThMgt_bTCoWarnReq, value=false
    ThMgt_bTrbWaPmpReq_out
      value:
        boolean literal ThMgt_bTrbWaPmpReq_out: type=DT_ThMgt_bTrbWaPmpReq, value=false
    ThMgt_nTarIdlHeatReq_out
      value:
        integer literal ThMgt_nTarIdlHeatReq_out: type=DT_ThMgt_nTarIdlHeatReq, value=0
    ThMgt_rCoHeatReq_out
      value:
        integer literal ThMgt_rCoHeatReq_out: type=DT_ThMgt_rCoHeatReq, value=0
    ThMgt_rOpBypCoVlvReq_out
      value:
        integer literal ThMgt_rOpBypCoVlvReq_out: type=DT_ThMgt_rOpBypCoVlvReq, value=0
    ThMgt_rOpHeatCoVlvReq_out
      value:
        integer literal ThMgt_rOpHeatCoVlvReq_out: type=DT_ThMgt_rOpHeatCoVlvReq, value=0
    ThMgt_rOpRadCoVlvReq_out
      value:
        integer literal ThMgt_rOpRadCoVlvReq_out: type=DT_ThMgt_rOpRadCoVlvReq, value=0
    ThMgt_rPwrECTReq_out
      value:
        integer literal ThMgt_rPwrECTReq_out: type=DT_ThMgt_rPwrECTReq, value=0
    ThMgt_rSpdFanReq_out
      value:
        integer literal ThMgt_rSpdFanReq_out: type=DT_ThMgt_rSpdFanReq, value=0
    ThMgt_stPosnCoVlvEstim_out
      value:
        integer literal ThMgt_stPosnCoVlvEstim_out: type=DT_ThMgt_stPosnCoVlvEstim, value=3
    ThMgt_stPosnFSFReq_out
      value:
        integer literal ThMgt_stPosnFSFReq_out: type=DT_ThMgt_stPosnFSFReq, value=0
    ThMgt_stSpdCoVlvReq_out
      value:
        integer literal ThMgt_stSpdCoVlvReq_out: type=DT_ThMgt_stSpdCoVlvReq, value=0
    ThMgt_tCoReg_in
      value:
        integer literal ThMgt_tCoReg_in: type=DT_ThMgt_tCoReg, value=105
    ThMgt_tCoReg_out
      value:
        integer literal ThMgt_tCoReg_out: type=DT_ThMgt_tCoReg, value=105
    ThMgt_tECTReq_out
      value:
        integer literal ThMgt_tECTReq_out: type=DT_ThMgt_tECTReq, value=105
    ThMgt_tiAcvTrbWaPmpEngStop_out
      value:
        integer literal ThMgt_tiAcvTrbWaPmpEngStop_out: type=DT_ThMgt_tiAcvTrbWaPmpEngStop, value=0
    ThMgt_wThFil_in
      value:
        integer literal ThMgt_wThFil_in: type=DT_ThMgt_wThFil, value=0
    ThMgt_wThFil_out
      value:
        integer literal ThMgt_wThFil_out: type=DT_ThMgt_wThFil, value=0
    TPMByp_bExThermoProt_Cst
      value:
        boolean literal TPMByp_bExThermoProt_Cst: type=DT_TPMByp_bExThermoProt, value=false
    TqCmp_bOpFSFReq_tAir_in
      value:
        boolean literal TqCmp_bOpFSFReq_tAir_in: type=DT_TqCmp_bOpFSFReq_tAir, value=false
    TqSysByp_tqIdcAirReqGen_Cst
      value:
        integer literal TqSysByp_tqIdcAirReqGen_Cst: type=DT_TqSysByp_tqIdcAirReqGen, value=0
    TRegClc_bEngWrm_Cst
      value:
        boolean literal TRegClc_bEngWrm_Cst: type=DT_TRegClc_bEngWrm, value=false
    TRegClc_bHiEngLd_Cst
      value:
        boolean literal TRegClc_bHiEngLd_Cst: type=DT_TRegClc_bHiEngLd, value=false
    TRegClc_bModRegCoVlv_Cst
      value:
        boolean literal TRegClc_bModRegCoVlv_Cst: type=DT_TRegClc_bModRegCoVlv, value=false
    TRegClc_tCoRegCoVlv_Cst
      value:
        integer literal TRegClc_tCoRegCoVlv_Cst: type=DT_TRegClc_tCoRegCoVlv, value=0
    TRegClc_tCoRegECT_Cst
      value:
        integer literal TRegClc_tCoRegECT_Cst: type=DT_TRegClc_tCoRegECT, value=0
    UndHoFil_nEngFil1_Cst
      value:
        integer literal UndHoFil_nEngFil1_Cst: type=DT_UndHoFil_nEngFil1, value=0
    UndHoFil_nEngFil2_Cst
      value:
        integer literal UndHoFil_nEngFil2_Cst: type=DT_UndHoFil_nEngFil2, value=0
    UndHoFil_spdVehFil1_Cst
      value:
        integer literal UndHoFil_spdVehFil1_Cst: type=DT_UndHoFil_spdVehFil1, value=0
    UndHoFil_spdVehFil2_Cst
      value:
        integer literal UndHoFil_spdVehFil2_Cst: type=DT_UndHoFil_spdVehFil2, value=0
    UndHoFil_tAirExtMesFil1_Cst
      value:
        integer literal UndHoFil_tAirExtMesFil1_Cst: type=DT_UndHoFil_tAirExtMesFil1, value=0
    UndHoFil_tAirExtMesFil2_Cst
      value:
        integer literal UndHoFil_tAirExtMesFil2_Cst: type=DT_UndHoFil_tAirExtMesFil2, value=0
    UndHoFil_tAirInMesFil_Cst
      value:
        integer literal UndHoFil_tAirInMesFil_Cst: type=DT_UndHoFil_tAirInMesFil, value=0
    UndHoFil_tqIdcEstimFil1_Cst
      value:
        integer literal UndHoFil_tqIdcEstimFil1_Cst: type=DT_UndHoFil_tqIdcEstimFil1, value=0
    UndHoFil_tqIdcEstimFil2_Cst
      value:
        integer literal UndHoFil_tqIdcEstimFil2_Cst: type=DT_UndHoFil_tqIdcEstimFil2, value=0
    UndHoFil_tUsPFltFil_Cst
      value:
        integer literal UndHoFil_tUsPFltFil_Cst: type=DT_UndHoFil_tUsPFltFil, value=0
    UndHoTMgt_bLoTCoRegReq_Cst
      value:
        boolean literal UndHoTMgt_bLoTCoRegReq_Cst: type=DT_UndHoTMgt_bLoTCoRegReq, value=false
    UndHoTMgt_tECTReq_Cst
      value:
        integer literal UndHoTMgt_tECTReq_Cst: type=DT_UndHoTMgt_tECTReq, value=0
    Veh_bHeatReq_in
      value:
        boolean literal Veh_bHeatReq_in: type=DT_Veh_bHeatReq, value=false
    Veh_bHeatWaPmpReq_in
      value:
        boolean literal Veh_bHeatWaPmpReq_in: type=DT_Veh_bHeatWaPmpReq, value=false
    Veh_stHeatCoFlowReq_in
      value:
        integer literal Veh_stHeatCoFlowReq_in: type=DT_Veh_stHeatCoFlowReq, value=0
    WaTEst_rErrTCo_in
      value:
        integer literal WaTEst_rErrTCo_in: type=DT_WaTEst_rErrTCo, value=0
    WaTEst_tMtlEngEstim_in
      value:
        integer literal WaTEst_tMtlEngEstim_in: type=DT_WaTEst_tMtlEngEstim, value=0
  internal behavior IB_ThMgt: component=THMGT
    operation invoked event EV_ThMgt_AftsNvramRead_1: start-on-event=RE_ThMgt_AftsNvramRead_1, operation=P_ThMgt_AftsNvramRead_1.op_ThMgt_AftsNvramRead_1
    timing event EV_ThMgt_003_TEV: mode-dependency=dependent-on-mode=R_UCE_stWkuMainRelSt.RCD_stWkuMainRelSt.Invalid, start-on-event=RE_ThMgt_003_TEV, period=0.2
    mode switch event EV_ThMgt_001_MSE: start-on-event=RE_ThMgt_001_MSE, activation=ENTRY, mode=R_EcuM_CurrentMode.currentMode.RUN
    timing event EV_ThMgt_004_TEV: mode-dependency=dependent-on-mode=R_UCE_stWkuMainRelSt.RCD_stWkuMainRelSt.Invalid, start-on-event=RE_ThMgt_004_TEV, period=0.1
    operation invoked event EV_ThMgt_AftsNvramWrite_1: start-on-event=RE_ThMgt_AftsNvramWrite_1, operation=P_ThMgt_AftsNvramWrite_1.op_ThMgt_AftsNvramWrite_1
    timing event EV_ThMgt_002_TEV: mode-dependency=dependent-on-mode=R_UCE_stWkuMainRelSt.RCD_stWkuMainRelSt.Invalid, start-on-event=RE_ThMgt_002_TEV, period=1
    95 x inter runnable variable, all with sw-calibration-access=READ-WRITE, communication-approach=EXPLICIT:
      UndHoFil_tqIdcEstimFil1: type=DT_UndHoFil_tqIdcEstimFil1, init-value=UndHoFil_tqIdcEstimFil1_Cst
      ExtByp_tAirUsCmprMes: type=DT_ExtByp_tAirUsCmprMes, init-value=ExtByp_tAirUsCmprMes_Cst
      ExtByp_stVSSCf: type=DT_ExtByp_stVSSCf, init-value=ExtByp_stVSSCf_Cst
      UndHoTMgt_tECTReq: type=DT_UndHoTMgt_tECTReq, init-value=UndHoTMgt_tECTReq_Cst
      PwtFil_nEngFil: type=DT_PwtFil_nEngFil, init-value=PwtFil_nEngFil_Cst
      CoPtByp_stCpl: type=DT_CoPtByp_stCpl, init-value=CoPtByp_stCpl_Cst
      PwtFil_tqIdcEstimFil: type=DT_PwtFil_tqIdcEstimFil, init-value=PwtFil_tqIdcEstimFil_Cst
      EGRCo_stSpdCoVlvReq: type=DT_EGRCo_stSpdCoVlvReq, init-value=EGRCo_stSpdCoVlvReq_Cst
      InpClc_tqIdcFld: sw-impl-policy=MEASUREMENT-POINT, sw-variable-access-impl-policy=OPTIMIZED, type=DT_InpClc_tqIdcFld, init-value=InpClc_tqIdcFld_Cst
      EGRCo_bOpCoVlvReq: type=DT_EGRCo_bOpCoVlvReq, init-value=EGRCo_bOpCoVlvReq_Cst
      GBxCo_tECTReqDly: type=DT_GBxCo_tECTReqDly, init-value=GBxCo_tECTReqDly_Cst
      ExtByp_tUsThrMes: type=DT_ExtByp_tUsThrMes, init-value=ExtByp_tUsThrMes_Cst
      FRMByp_bInhDiagCoBoilLim: type=DT_FRMByp_bInhDiagCoBoilLim, init-value=FRMByp_bInhDiagCoBoilLim_Cst
      KnkProt_tECTTAirReq: type=DT_KnkProt_tECTTAirReq, init-value=KnkProt_tECTTAirReq_Cst
      StgByp_agStrWhl: type=DT_StgByp_agStrWhl, init-value=StgByp_agStrWhl_Cst
      InpClc_tqIdcEstim: type=DT_InpClc_tqIdcEstim, init-value=InpClc_tqIdcEstim_Cst
      UndHoFil_tAirExtMesFil1: type=DT_UndHoFil_tAirExtMesFil1, init-value=UndHoFil_tAirExtMesFil1_Cst
      OAMByp_rOilDil: type=DT_OAMByp_rOilDil, init-value=OAMByp_rOilDil_Cst
      EngMByp_mfEgEstim: type=DT_EngMByp_mfEgEstim, init-value=EngMByp_mfEgEstim_Cst
      EngLimByp_tqIdcEngCur: type=DT_EngLimByp_tqIdcEngCur, init-value=EngLimByp_tqIdcEngCur
      KnkProt_tECTAdpReq: type=DT_KnkProt_tECTAdpReq, init-value=KnkProt_tECTAdpReq_Cst
      TqSysByp_tqIdcAirReqGen: type=DT_TqSysByp_tqIdcAirReqGen, init-value=TqSysByp_tqIdcAirReqGen_Cst
      AtyModMgt_bLoTCoRegReq: type=DT_AtyModMgt_bLoTCoRegReq, init-value=AtyModMgt_bLoTCoRegReq_Cst
      FRMByp_bInhTCoColdDiag: type=DT_FRMByp_bInhTCoColdDiag, init-value=FRMByp_bInhTCoColdDiag_Cst
      CoPtByp_bTqTx: type=DT_CoPtByp_bTqTx, init-value=CoPtByp_bTqTx_Cst
      InpClc_bACCf: type=DT_InpClc_bACCf, init-value=InpClc_bACCf_Cst
      UndHoFil_nEngFil2: type=DT_UndHoFil_nEngFil2, init-value=UndHoFil_nEngFil2_Cst
      ThEClc_wThFil2: type=DT_ThEClc_wThFil2, init-value=ThEClc_wThFil2_Cst
      ExtByp_tUsPFlt: type=DT_ExtByp_tUsPFlt, init-value=ExtByp_tUsPFlt_Cst
      CmptFil_agvStrWhlFil: type=DT_CmptFil_agvStrWhlFil, init-value=CmptFil_agvStrWhlFil_Cst
      FRMByp_bAcvBoilLimChg: type=DT_FRMByp_bAcvBoilLimChg, init-value=FRMByp_bAcvBoilLimChg_Cst
      ExtByp_nEng: type=DT_ExtByp_nEng, init-value=ExtByp_nEng_Cst
      AntiBoil_tCoMesFil: type=DT_AntiBoil_tCoMesFil, init-value=AntiBoil_tCoMesFil_Cst
      FRMByp_bAcvVeryLoTCoReg: type=DT_FRMByp_bAcvVeryLoTCoReg, init-value=FRMByp_bAcvVeryLoTCoReg_Cst
      ExtByp_bFSFCf: type=DT_ExtByp_bFSFCf, init-value=ExtByp_bFSFCf_Cst
      AntiBoil_tECTReqDly: type=DT_AntiBoil_tECTReqDly, init-value=AntiBoil_tECTReqDly_Cst
      CoAftsMgt_tECTAftsReq: type=DT_CoAftsMgt_tECTAftsReq, init-value=CoAftsMgt_tECTAftsReq_Cst
      ExtByp_tDsThrMes: type=DT_ExtByp_tDsThrMes, init-value=ExtByp_tDsThrMes_Cst
      CoPtByp_noEgdGearCord: type=DT_CoPtByp_noEgdGearCord, init-value=CoPtByp_noEgdGearCord_Cst
      ExtByp_tCoMes: type=DT_ExtByp_tCoMes, init-value=ExtByp_tCoMes_Cst
      UndHoFil_spdVehFil2: type=DT_UndHoFil_spdVehFil2, init-value=UndHoFil_spdVehFil2_Cst
      UndHoFil_tAirExtMesFil2: type=DT_UndHoFil_tAirExtMesFil2, init-value=UndHoFil_tAirExtMesFil2_Cst
      PFltByp_bPFltRgnSrvReq: type=DT_PFltByp_bPFltRgnSrvReq, init-value=PFltByp_bPFltRgnSrvReq_Cst
      TRegClc_tCoRegCoVlv: type=DT_TRegClc_tCoRegCoVlv, init-value=TRegClc_tCoRegCoVlv_Cst
      FRMByp_bAcvNoEgdGearDft: type=DT_FRMByp_bAcvNoEgdGearDft, init-value=FRMByp_bAcvNoEgdGearDft_Cst
      StgByp_agvStrWhl: type=DT_StgByp_agvStrWhl, init-value=StgByp_agvStrWhl_Cst
      CmptFil_agStrWhlFil: type=DT_CmptFil_agStrWhlFil, init-value=CmptFil_agStrWhlFil_Cst
      ExtByp_tAirExtMes: type=DT_ExtByp_tAirExtMes, init-value=ExtByp_tAirExtMes_Cst
      UndHoFil_tAirInMesFil: type=DT_UndHoFil_tAirInMesFil, init-value=UndHoFil_tAirInMesFil_Cst
      ExtByp_stGBxCf: type=DT_ExtByp_stGBxCf, init-value=ExtByp_stGBxCf_Cst
      InpClc_tAirInMes: type=DT_InpClc_tAirInMes, init-value=InpClc_tAirInMes_Cst
      UndHoTMgt_bLoTCoRegReq: type=DT_UndHoTMgt_bLoTCoRegReq, init-value=UndHoTMgt_bLoTCoRegReq_Cst
      PwtFil_tCoRegFil2: type=DT_PwtFil_tCoRegFil2, init-value=PwtFil_tCoRegFil2_Cst
      EngMByp_mfDsEGRCoEstim: type=DT_EngMByp_mfDsEGRCoEstim, init-value=EngMByp_mfDsEGRCoEstim_Cst
      InpClc_tEg: type=DT_InpClc_tEg, init-value=InpClc_tEg_Cst
      CoVlvCtl_bRstStopHldDly: type=DT_CoVlvCtl_bRstStopHldDly, init-value=CoVlvCtl_bRstStopHldDly_Cst
      TPMByp_bExThermoProt: type=DT_TPMByp_bExThermoProt, init-value=TPMByp_bExThermoProt_Cst
      InpClc_bEngRun: type=DT_InpClc_bEngRun, init-value=InpClc_bEngRun_Cst
      UndHoFil_tUsPFltFil: type=DT_UndHoFil_tUsPFltFil, init-value=UndHoFil_tUsPFltFil_Cst
      AirSysByp_rOpEGRCoBypReq: type=DT_AirSysByp_rOpEGRCoBypReq, init-value=AirSysByp_rOpEGRCoBypReq_Cst
      InpClc_bPFltRgnReq: type=DT_InpClc_bPFltRgnReq, init-value=InpClc_bPFltRgnReq_Cst
      EOMByp_tiEngStop: type=DT_EOMByp_tiEngStop, init-value=EOMByp_tiEngStop_Cst
      FRMByp_bDeacCoBoilLim: type=DT_FRMByp_bDeacCoBoilLim, init-value=FRMByp_bDeacCoBoilLim_Cst
      KnkMgtByp_ctRblInjCutOffPtl: type=DT_KnkMgtByp_ctRblInjCutOffPtl, init-value=KnkMgtByp_ctRblInjCutOffPtl_Cst
      ExtByp_tFuMes: type=DT_ExtByp_tFuMes, init-value=ExtByp_tFuMes_Cst
      ExtByp_bKeyOff: type=DT_ExtByp_bKeyOff, init-value=ExtByp_bKeyOff_Cst
      AntiBoil_bRatCorPwrFilIniDly: type=DT_AntiBoil_bRatCorPwrFilIniDly, init-value=AntiBoil_bRatCorPwrFilIniDly_Cst
      ExtByp_tCoMesFineResl2: type=DT_ExtByp_tCoMesFineResl2, init-value=ExtByp_tCoMesFineResl2_Cst
      TRegClc_bEngWrm: type=DT_TRegClc_bEngWrm, init-value=TRegClc_bEngWrm_Cst
      ExtByp_spdVeh: type=DT_ExtByp_spdVeh, init-value=ExtByp_spdVeh_Cst
      InpClc_bEngStop: type=DT_InpClc_bEngStop, init-value=InpClc_bEngStop_Cst
      InThMByp_tAirUsInVlvEstim: type=DT_InThMByp_tAirUsInVlvEstim, init-value=InThMByp_tAirUsInVlvEstim_Cst
      TRegClc_bModRegCoVlv: type=DT_TRegClc_bModRegCoVlv, init-value=TRegClc_bModRegCoVlv_Cst
      UndHoFil_spdVehFil1: type=DT_UndHoFil_spdVehFil1, init-value=UndHoFil_spdVehFil1_Cst
      EOMByp_stCmbTdOff: type=DT_EOMByp_stCmbTdOff, init-value=EOMByp_stCmbTdOff_Cst
      AntiBoil_rCorPwrFil: type=DT_AntiBoil_rCorPwrFil, init-value=AntiBoil_rCorPwrFil_Cst
      PwtFil_tCoRegFil1: type=DT_PwtFil_tCoRegFil1, init-value=PwtFil_tCoRegFil1_Cst
      FRMByp_bAcvLoTCoReg: type=DT_FRMByp_bAcvLoTCoReg, init-value=FRMByp_bAcvLoTCoReg_Cst
      ExtByp_pAirExtMes: type=DT_ExtByp_pAirExtMes, init-value=ExtByp_pAirExtMes_Cst
      FRMByp_bAcvTrbWaPmp: type=DT_FRMByp_bAcvTrbWaPmp, init-value=FRMByp_bAcvTrbWaPmp_Cst
      PwtFil_tCoRegFil3: type=DT_PwtFil_tCoRegFil3, init-value=ConstantValue2
      EGRVlvByp_rOp: type=DT_EGRVlvByp_rOp, init-value=EGRVlvByp_rOp_Cst
      InpClc_tCAC: type=DT_InpClc_tCAC, init-value=InpClc_tCAC_Cst
      UndHoFil_tqIdcEstimFil2: type=DT_UndHoFil_tqIdcEstimFil2, init-value=UndHoFil_tqIdcEstimFil2_Cst
      ExtByp_tOilMes: type=DT_ExtByp_tOilMes, init-value=ExtByp_tOilMes_Cst
      ExtByp_tECTSp: type=DT_ExtByp_tECTSp, init-value=ExtByp_tECTSp_Cst
      IgSysByp_bAcvLoTCoRegKnk: type=DT_IgSysByp_bAcvLoTCoRegKnk, init-value=IgSysByp_bAcvLoTCoRegKnk_Cst
      AtyModMgt_tECTReq: type=DT_AtyModMgt_tECTReq, init-value=AtyModMgt_tECTReq_Cst
      CmptFil_tCACFil: type=DT_CmptFil_tCACFil, init-value=CmptFil_tCACFil_Cst
      UndHoFil_nEngFil1: type=DT_UndHoFil_nEngFil1, init-value=UndHoFil_nEngFil1_Cst
      OilDilProt_bLoTCoRegReq: type=DT_OilDilProt_bLoTCoRegReq, init-value=OilDilProt_bLoTCoRegReq_Cst
      ESLimByp_bAcvTrqLim: type=DT_ESLimByp_bAcvTrqLim, init-value=ESLimByp_bAcvTrqLim_Cst
      InpClc_bPwtRun: type=DT_InpClc_bPwtRun, init-value=InpClc_bPwtRun_Cst
      TRegClc_tCoRegECT: type=DT_TRegClc_tCoRegECT, init-value=TRegClc_tCoRegECT_Cst
      TRegClc_bHiEngLd: type=DT_TRegClc_bHiEngLd, init-value=TRegClc_bHiEngLd_Cst
    6 x runnable:
      RE_ThMgt_004_TEV: read-variable=[InpClc_bEngStop, AntiBoil_rCorPwrFil, ExtByp_tAirExtMes, InThMByp_tAirUsInVlvEstim, FRMByp_bInhDiagCoBoilLim, IgSysByp_bAcvLoTCoRegKnk, ExtByp_spdVeh, ExtByp_tCoMesFineResl2, InpClc_bEngRun, FRMByp_bAcvBoilLimChg, PwtFil_tCoRegFil3, FRMByp_bDeacCoBoilLim], written-variable=[ExtByp_nEng, EngMByp_mfEgEstim, PFltByp_bPFltRgnSrvReq, CoPtByp_stCpl, KnkProt_tECTAdpReq, InpClc_tqIdcEstim, EGRVlvByp_rOp, ESLimByp_bAcvTrqLim, EngLimByp_tqIdcEngCur, EOMByp_tiEngStop, CoPtByp_bTqTx, EngMByp_mfDsEGRCoEstim, KnkMgtByp_ctRblInjCutOffPtl, FRMByp_bAcvNoEgdGearDft, AirSysByp_rOpEGRCoBypReq, CoPtByp_noEgdGearCord, KnkProt_tECTTAirReq, OAMByp_rOilDil, TqSysByp_tqIdcAirReqGen, InpClc_bPFltRgnReq, InpClc_tqIdcFld, FRMByp_bAcvTrbWaPmp, EOMByp_stCmbTdOff, ExtByp_pAirExtMes, AntiBoil_bRatCorPwrFilIniDly, AntiBoil_tCoMesFil, StgByp_agvStrWhl, StgByp_agStrWhl, TPMByp_bExThermoProt, AntiBoil_tECTReqDly]
        29 x data receive point:
          dr_IgSys_tqIdcEstim: data-element=R_IgSys_tqIdcEstim.IgSys_tqIdcEstim
          dr_EGRVlv_rOp: data-element=R_EGRVlv_rOp.EGRVlv_rOp
          dr_AirSys_rOpEGRCoBypReq: data-element=R_AirSys_rOpEGRCoBypReq.AirSys_rOpEGRCoBypReq
          dr_EngM_mfEgEstim: data-element=R_EngM_mfEgEstim.EngM_mfEgEstim
          dr_CoPt_bTqTx: data-element=R_CoPt_bTqTx.CoPt_bTqTx
          dr_TqEst_tqIdcEstim: data-element=R_TqEst_tqIdcEstim.TqEst_tqIdcEstim
          dr_Ext_nEng: data-element=R_Ext_nEng.Ext_nEng
          dr_PFlt_bPFltRgnReq: data-element=R_PFlt_bPFltRgnReq.PFlt_bPFltRgnReq
          dr_TqSys_tqIdcAirReqGen: data-element=R_TqSys_tqIdcAirReqGen.TqSys_tqIdcAirReqGen
          dr_ESLim_bAcvTrqLim: data-element=R_ESLim_bAcvTrqLim.ESLim_bAcvTrqLim
          dr_TqRes_tqMaxRes: data-element=R_TqRes_tqMaxRes.TqRes_tqMaxRes
          dr_TPM_bExThermoProt: data-element=R_TPM_bExThermoProt.TPM_bExThermoProt
          dr_ExM_mfEgWoutEGR: data-element=R_ExM_mfEgWoutEGR.ExM_mfEgWoutEGR
          dr_CoPt_stCpl: data-element=R_CoPt_stCpl.CoPt_stCpl
          dr_PFlt_bPFltRgnSrvReq: data-element=R_PFlt_bPFltRgnSrvReq.PFlt_bPFltRgnSrvReq
          dr_EngLim_tqIdcEngCur: data-element=R_EngLim_tqIdcEngCur.EngLim_tqIdcEngCur
          dr_Stg_agvStrWhl: data-element=R_Stg_agvStrWhl.Stg_agvStrWhl
          dr_EOM_stCmbTdOff: data-element=R_EOM_stCmbTdOff.EOM_stCmbTdOff
          dr_EngLim_tqIdcFLdUnlim: data-element=R_EngLim_tqIdcFLdUnlim.EngLim_tqIdcFLdUnlim
          dr_Stg_agStrWhl: data-element=R_Stg_agStrWhl.Stg_agStrWhl
          dr_Ext_pAirExtMes: data-element=R_Ext_pAirExtMes.Ext_pAirExtMes
          dr_EngLim_tqIdcAdvOptmTrbMax: data-element=R_EngLim_tqIdcAdvOptmTrbMax.EngLim_tqIdcAdvOptmTrbMax
          dr_CoPt_noEgdGearCord: data-element=R_CoPt_noEgdGearCord.CoPt_noEgdGearCord
          dr_EngM_mfDsEGRCoEstim: data-element=R_EngM_mfDsEGRCoEstim.EngM_mfDsEGRCoEstim
          dr_KnkMgt_prm_ctRblInjCutOffPtl: data-element=R_KnkMgt_prm_ctRblInjCutOffPtl.KnkMgt_prm_ctRblInjCutOffPtl
          dr_ThMgt_tCoReg: data-element=R_ThMgt_tCoReg.ThMgt_tCoReg
          dr_EOM_stEngModReq: data-element=R_EOM_stEngModReq.EOM_stEngModReq
          dr_OAM_rOilDil: data-element=R_OAM_rOilDil.OAM_rOilDil
          dr_EOM_tiEngStop: data-element=R_EOM_tiEngStop.EOM_tiEngStop
        data send point ds_ThMgt_tqIdcLimReq: data-element=P_ThMgt_tqIdcLimReq.ThMgt_tqIdcLimReq
        5 x sync call:
          ssp_FRM_bAcvThMgtRcvValMfEg: operation=R_FRM_bAcvThMgtRcvValMfEg.GetFunctionPermission
          ssp_FRM_bAcvThMgtRcvValTqIdc: operation=R_FRM_bAcvThMgtRcvValTqIdc.GetFunctionPermission
          ssp_FRM_bAcvNoEgdGearDft: operation=R_FRM_bAcvNoEgdGearDft.GetFunctionPermission
          ssp_ThMgt_AntiBoil: operation=R_ThMgt_AntiBoil.SetEventStatus
          ssp_FRM_bAcvTrbWaPmp: operation=R_FRM_bAcvTrbWaPmp.GetFunctionPermission
      RE_ThMgt_AftsNvramRead_1
      RE_ThMgt_001_MSE: written-variable=[TRegClc_bHiEngLd, KnkProt_tECTTAirReq, PwtFil_tCoRegFil1, PwtFil_tqIdcEstimFil, InpClc_bEngRun, UndHoFil_tAirInMesFil, FRMByp_bAcvBoilLimChg, PwtFil_tCoRegFil2, EOMByp_stCmbTdOff, KnkMgtByp_ctRblInjCutOffPtl, ESLimByp_bAcvTrqLim, UndHoFil_tAirExtMesFil1, ExtByp_stVSSCf, PwtFil_nEngFil, TRegClc_bModRegCoVlv, InpClc_bEngStop, InpClc_bPFltRgnReq, FRMByp_bAcvVeryLoTCoReg, AntiBoil_rCorPwrFil, ExtByp_spdVeh, ExtByp_tFuMes, EGRVlvByp_rOp, EGRCo_bOpCoVlvReq, EngMByp_mfEgEstim, ExtByp_tECTSp, InpClc_bPwtRun, AtyModMgt_tECTReq, CoAftsMgt_tECTAftsReq, ExtByp_tCoMes, TRegClc_tCoRegECT, ExtByp_tAirUsCmprMes, EOMByp_tiEngStop, FRMByp_bInhDiagCoBoilLim, CmptFil_agStrWhlFil, CoPtByp_stCpl, UndHoTMgt_bLoTCoRegReq, CoVlvCtl_bRstStopHldDly, ExtByp_pAirExtMes, InpClc_bACCf, UndHoFil_tqIdcEstimFil1, ExtByp_tAirExtMes, FRMByp_bAcvNoEgdGearDft, ExtByp_tUsThrMes, ExtByp_bKeyOff, ExtByp_tCoMesFineResl2, OAMByp_rOilDil, ThEClc_wThFil2, UndHoFil_spdVehFil2, InpClc_tAirInMes, AntiBoil_bRatCorPwrFilIniDly, InpClc_tCAC, AirSysByp_rOpEGRCoBypReq, InpClc_tqIdcFld, ExtByp_nEng, TRegClc_bEngWrm, UndHoFil_nEngFil2, IgSysByp_bAcvLoTCoRegKnk, AtyModMgt_bLoTCoRegReq, FRMByp_bAcvLoTCoReg, UndHoFil_nEngFil1, AntiBoil_tCoMesFil, CmptFil_agvStrWhlFil, GBxCo_tECTReqDly, UndHoTMgt_tECTReq, StgByp_agStrWhl, OilDilProt_bLoTCoRegReq, CoPtByp_bTqTx, InpClc_tqIdcEstim, EGRCo_stSpdCoVlvReq, UndHoFil_tUsPFltFil, ExtByp_bFSFCf, InThMByp_tAirUsInVlvEstim, TqSysByp_tqIdcAirReqGen, StgByp_agvStrWhl, CoPtByp_noEgdGearCord, InpClc_tEg, AntiBoil_tECTReqDly, FRMByp_bInhTCoColdDiag, PFltByp_bPFltRgnSrvReq, EngMByp_mfDsEGRCoEstim, FRMByp_bDeacCoBoilLim, UndHoFil_tAirExtMesFil2, CmptFil_tCACFil, TRegClc_tCoRegCoVlv, EngLimByp_tqIdcEngCur, ExtByp_tUsPFlt, ExtByp_stGBxCf, ExtByp_tDsThrMes, ExtByp_tOilMes, UndHoFil_tqIdcEstimFil2, FRMByp_bAcvTrbWaPmp, PwtFil_tCoRegFil3, UndHoFil_spdVehFil1, TPMByp_bExThermoProt, KnkProt_tECTAdpReq]
        38 x data send point:
          ds_ThMgt_bTCoWarnReq: data-element=P_ThMgt_bTCoWarnReq.ThMgt_bTCoWarnReq
          ds_ThMgt_bIncVoltReq: data-element=P_ThMgt_bIncVoltReq.ThMgt_bIncVoltReq
          ds_ThMgt_stSpdCoVlvReq: data-element=P_ThMgt_stSpdCoVlvReq.ThMgt_stSpdCoVlvReq
          ds_ThMgt_rPwrECTReq: data-element=P_ThMgt_rPwrECTReq.ThMgt_rPwrECTReq
          ds_ThMgt_bPwrHldTrbWaPmpReq: data-element=P_ThMgt_bPwrHldTrbWaPmpReq.ThMgt_bPwrHldTrbWaPmpReq
          ds_ThMgt_bHldPosnCoVlvReq: data-element=P_ThMgt_bHldPosnCoVlvReq.ThMgt_bHldPosnCoVlvReq
          ds_ThMgt_bPwrHldAdFanReq: data-element=P_ThMgt_bPwrHldAdFanReq.ThMgt_bPwrHldAdFanReq
          ds_ThMgt_bECTAftsReq: data-element=P_ThMgt_bECTAftsReq.ThMgt_bECTAftsReq
          ds_ThMgt_rOpHeatCoVlvReq: data-element=P_ThMgt_rOpHeatCoVlvReq.ThMgt_rOpHeatCoVlvReq
          ds_ThMgt_bECUFanReq: data-element=P_ThMgt_bECUFanReq.ThMgt_bECUFanReq
          ds_ThMgt_bEHRWaPmpReq: data-element=P_ThMgt_bEHRWaPmpReq.ThMgt_bEHRWaPmpReq
          ds_ThMgt_nTarIdlHeatReq: data-element=P_ThMgt_nTarIdlHeatReq.ThMgt_nTarIdlHeatReq
          ds_ThMgt_bPwrHldCoVlvReq: data-element=P_ThMgt_bPwrHldCoVlvReq.ThMgt_bPwrHldCoVlvReq
          ds_ThMgt_bEndCtlCoVlv: data-element=P_ThMgt_bEndCtlCoVlv.ThMgt_bEndCtlCoVlv
          ds_ThMgt_bMainWaPmpSt: data-element=P_ThMgt_bMainWaPmpSt.ThMgt_bMainWaPmpSt
          ds_ThMgt_wThFil: data-element=P_ThMgt_wThFil.ThMgt_wThFil
          ds_ThMgt_bPwrHldFSFReq: data-element=P_ThMgt_bPwrHldFSFReq.ThMgt_bPwrHldFSFReq
          ds_ThMgt_rSpdFanReq: data-element=P_ThMgt_rSpdFanReq.ThMgt_rSpdFanReq
          ds_ThMgt_stPosnFSFReq: data-element=P_ThMgt_stPosnFSFReq.ThMgt_stPosnFSFReq
          ds_ThMgt_tqIdcLimReq: data-element=P_ThMgt_tqIdcLimReq.ThMgt_tqIdcLimReq
          ds_ThMgt_bAcvR1234Mgt: data-element=P_ThMgt_bAcvR1234Mgt.ThMgt_bAcvR1234Mgt
          ds_ThMgt_bACCmprOffReq: data-element=P_ThMgt_bACCmprOffReq.ThMgt_bACCmprOffReq
          ds_ThMgt_bBattFanReq: data-element=P_ThMgt_bBattFanReq.ThMgt_bBattFanReq
          ds_ThMgt_bRstrtReq: data-element=P_ThMgt_bRstrtReq.ThMgt_bRstrtReq
          ds_ThMgt_tECTReq: data-element=P_ThMgt_tECTReq.ThMgt_tECTReq
          ds_ThMgt_bTrbWaPmpReq: data-element=P_ThMgt_bTrbWaPmpReq.ThMgt_bTrbWaPmpReq
          ds_ThMgt_tiAcvTrbWaPmpEngStop: data-element=P_ThMgt_tiAcvTrbWaPmpEngStop.ThMgt_tiAcvTrbWaPmpEngStop
          ds_ThMgt_rCoHeatReq: data-element=P_ThMgt_rCoHeatReq.ThMgt_rCoHeatReq
          ds_ThMgt_bPwrHldMainFanReq: data-element=P_ThMgt_bPwrHldMainFanReq.ThMgt_bPwrHldMainFanReq
          ds_ThMgt_stPosnCoVlvEstim: data-element=P_ThMgt_stPosnCoVlvEstim.ThMgt_stPosnCoVlvEstim
          ds_ThMgt_rOpRadCoVlvReq: data-element=P_ThMgt_rOpRadCoVlvReq.ThMgt_rOpRadCoVlvReq
          ds_ThMgt_bHeatWaPmpReq: data-element=P_ThMgt_bHeatWaPmpReq.ThMgt_bHeatWaPmpReq
          ds_ThMgt_tCoReg: data-element=P_ThMgt_tCoReg.ThMgt_tCoReg
          ds_ThMgt_bAdFanReq: data-element=P_ThMgt_bAdFanReq.ThMgt_bAdFanReq
          ds_ThMgt_rOpBypCoVlvReq: data-element=P_ThMgt_rOpBypCoVlvReq.ThMgt_rOpBypCoVlvReq
          ds_ThMgt_bEHRHeatReq: data-element=P_ThMgt_bEHRHeatReq.ThMgt_bEHRHeatReq
          ds_ThMgt_bMainWaPmpReq: data-element=P_ThMgt_bMainWaPmpReq.ThMgt_bMainWaPmpReq
          ds_ThMgt_bPosnFSF: data-element=P_ThMgt_bPosnFSF.ThMgt_bPosnFSF
      RE_ThMgt_003_TEV: read-variable=[InpClc_tCAC, ExtByp_tOilMes, CoVlvCtl_bRstStopHldDly, UndHoTMgt_bLoTCoRegReq, ExtByp_tUsThrMes, AntiBoil_tECTReqDly, EngMByp_mfDsEGRCoEstim, InpClc_tEg, StgByp_agvStrWhl, AirSysByp_rOpEGRCoBypReq, ExtByp_tFuMes, FRMByp_bAcvVeryLoTCoReg, AtyModMgt_bLoTCoRegReq, StgByp_agStrWhl, ExtByp_tECTSp, KnkProt_tECTTAirReq, EOMByp_tiEngStop, ExtByp_tCoMes, ExtByp_tDsThrMes, FRMByp_bInhTCoColdDiag, InpClc_tqIdcEstim, UndHoTMgt_tECTReq, ExtByp_tAirExtMes, ExtByp_tUsPFlt, ExtByp_nEng, EngMByp_mfEgEstim, CoAftsMgt_tECTAftsReq, AtyModMgt_tECTReq, OilDilProt_bLoTCoRegReq, ExtByp_tAirUsCmprMes, InpClc_tAirInMes, EGRVlvByp_rOp, FRMByp_bAcvLoTCoReg, KnkProt_tECTAdpReq, GBxCo_tECTReqDly], written-variable=[ExtByp_bFSFCf, EGRCo_bOpCoVlvReq, PwtFil_tCoRegFil2, CmptFil_agStrWhlFil, ExtByp_spdVeh, CmptFil_agvStrWhlFil, ExtByp_bKeyOff, UndHoFil_nEngFil1, PwtFil_tqIdcEstimFil, ExtByp_stVSSCf, TRegClc_tCoRegCoVlv, TRegClc_tCoRegECT, UndHoFil_tAirExtMesFil2, TRegClc_bEngWrm, UndHoFil_tqIdcEstimFil2, ThEClc_wThFil2, TRegClc_bHiEngLd, PwtFil_nEngFil, CmptFil_tCACFil, PwtFil_tCoRegFil3, InpClc_bPwtRun, UndHoFil_tqIdcEstimFil1, UndHoFil_tUsPFltFil, EGRCo_stSpdCoVlvReq, TRegClc_bModRegCoVlv, InpClc_bACCf, UndHoFil_nEngFil2, ExtByp_stGBxCf, PwtFil_tCoRegFil1, InpClc_bEngRun, UndHoFil_spdVehFil2, UndHoFil_tAirExtMesFil1, InpClc_bEngStop, UndHoFil_tAirInMesFil, UndHoFil_spdVehFil1]
        9 x data receive point:
          dr_Ext_stVSSCf: data-element=R_Ext_stVSSCf.Ext_stVSSCf
          dr_CoPTSt_stEng: data-element=R_CoPTSt_stEng.CoPTSt_stEng
          dr_Ext_bKeyOff: data-element=R_Ext_bKeyOff.Ext_bKeyOff
          dr_CoPtFH_stPwt: data-element=R_CoPtFH_stPwt.CoPtFH_stPwt
          dr_Ext_bFSFCf: data-element=R_Ext_bFSFCf.Ext_bFSFCf
          dr_Ext_stGBxCf: data-element=R_Ext_stGBxCf.Ext_stGBxCf
          dr_Ext_spdVeh: data-element=R_Ext_spdVeh.Ext_spdVeh
          dr_Ext_bACCf: data-element=R_Ext_bACCf.Ext_bACCf
          dr_Ext_stACTypCf: data-element=R_Ext_stACTypCf.Ext_stACTypCf
        data send point ds_ThMgt_tCoReg: data-element=P_ThMgt_tCoReg.ThMgt_tCoReg
        data send point ds_ThMgt_wThFil: data-element=P_ThMgt_wThFil.ThMgt_wThFil
        sync call ssp_ThMgt_TCoUndEstim: operation=R_ThMgt_TCoUndEstim.SetEventStatus
        sync call ssp_ThMgt_TCoOverEstim: operation=R_ThMgt_TCoOverEstim.SetEventStatus
      RE_ThMgt_002_TEV: read-variable=[ThEClc_wThFil2, InpClc_bACCf, InpClc_tqIdcEstim, ExtByp_bFSFCf, FRMByp_bAcvNoEgdGearDft, CoPtByp_bTqTx, PFltByp_bPFltRgnSrvReq, PwtFil_nEngFil, ESLimByp_bAcvTrqLim, ExtByp_spdVeh, AntiBoil_bRatCorPwrFilIniDly, PwtFil_tCoRegFil2, CoPtByp_stCpl, CmptFil_agvStrWhlFil, UndHoFil_tAirInMesFil, UndHoFil_spdVehFil2, UndHoFil_nEngFil2, InpClc_bPFltRgnReq, AntiBoil_tCoMesFil, TPMByp_bExThermoProt, CmptFil_agStrWhlFil, ExtByp_stVSSCf, PwtFil_tqIdcEstimFil, ExtByp_nEng, TRegClc_bHiEngLd, EOMByp_stCmbTdOff, CoPtByp_noEgdGearCord, TqSysByp_tqIdcAirReqGen, UndHoFil_nEngFil1, EGRCo_bOpCoVlvReq, UndHoFil_tqIdcEstimFil1, TRegClc_bModRegCoVlv, KnkMgtByp_ctRblInjCutOffPtl, EOMByp_tiEngStop, InpClc_bEngRun, UndHoFil_tqIdcEstimFil2, InpClc_tqIdcFld, ExtByp_bKeyOff, UndHoFil_tAirExtMesFil1, InpClc_bPwtRun, OAMByp_rOilDil, ExtByp_pAirExtMes, TRegClc_tCoRegECT, EGRCo_stSpdCoVlvReq, PwtFil_tCoRegFil1, ExtByp_stGBxCf, InpClc_bEngStop, CmptFil_tCACFil, UndHoFil_tUsPFltFil, FRMByp_bAcvTrbWaPmp, TRegClc_tCoRegCoVlv, UndHoFil_spdVehFil1, TRegClc_bEngWrm, UndHoFil_tAirExtMesFil2, EngLimByp_tqIdcEngCur], written-variable=[ExtByp_tUsThrMes, FRMByp_bAcvLoTCoReg, FRMByp_bDeacCoBoilLim, ExtByp_tAirUsCmprMes, InpClc_tEg, UndHoTMgt_bLoTCoRegReq, AntiBoil_rCorPwrFil, ExtByp_tCoMes, FRMByp_bInhTCoColdDiag, CoAftsMgt_tECTAftsReq, ExtByp_tUsPFlt, AtyModMgt_tECTReq, ExtByp_tOilMes, ExtByp_tFuMes, AntiBoil_tECTReqDly, UndHoTMgt_tECTReq, AtyModMgt_bLoTCoRegReq, ExtByp_tDsThrMes, ExtByp_tCoMesFineResl2, InThMByp_tAirUsInVlvEstim, FRMByp_bAcvVeryLoTCoReg, IgSysByp_bAcvLoTCoRegKnk, CoVlvCtl_bRstStopHldDly, FRMByp_bInhDiagCoBoilLim, OilDilProt_bLoTCoRegReq, InpClc_tCAC, ExtByp_tAirExtMes, GBxCo_tECTReqDly, FRMByp_bAcvBoilLimChg, ExtByp_tECTSp, InpClc_tAirInMes]
        42 x data receive point:
          dr_AC_rSpdFanReq: data-element=R_AC_rSpdFanReq.AC_rSpdFanReq
          dr_CoPt_rSpdFanReqProtManClu: data-element=R_CoPt_rSpdFanReqProtManClu.CoPt_rSpdFanReqProtManClu
          dr_Ext_stSpdFanPFltReq: data-element=R_Ext_stSpdFanPFltReq.Ext_stSpdFanPFltReq
          dr_IgSys_bAcvLoTCoRegKnk: data-element=R_IgSys_bAcvLoTCoRegKnk.IgSys_bAcvLoTCoRegKnk
          dr_Ext_tCoMesFineResl2: data-element=R_Ext_tCoMesFineResl2.Ext_tCoMesFineResl2
          dr_Ext_tVSS: data-element=R_Ext_tVSS.Ext_tVSS
          dr_Ext_tDsThrMes: data-element=R_Ext_tDsThrMes.Ext_tDsThrMes
          dr_WaTEst_rErrTCo: data-element=R_WaTEst_rErrTCo.WaTEst_rErrTCo
          dr_AC_bOpFSFReq: data-element=R_AC_bOpFSFReq.AC_bOpFSFReq
          dr_EngM_tUsTrbEstimFil: data-element=R_EngM_tUsTrbEstimFil.EngM_tUsTrbEstimFil
          dr_Ext_tUsThrMes: data-element=R_Ext_tUsThrMes.Ext_tUsThrMes
          dr_Ext_tUsPFlt: data-element=R_Ext_tUsPFlt.Ext_tUsPFlt
          dr_CoVlv_rOpHeatCoVlvMes: data-element=R_CoVlv_rOpHeatCoVlvMes.CoVlv_rOpHeatCoVlvMes
          dr_ElSysCo_rSpdFanReq: data-element=R_ElSysCo_rSpdFanReq.ElSysCo_rSpdFanReq
          dr_Veh_stHeatCoFlowReq: data-element=R_Veh_stHeatCoFlowReq.Veh_stHeatCoFlowReq
          dr_Afts_bAcvFSF: data-element=R_Afts_bAcvFSF.Afts_bAcvFSF
          dr_Ext_tECTSp: data-element=R_Ext_tECTSp.Ext_tECTSp
          dr_CoVlv_rOpBypCoVlvMes: data-element=R_CoVlv_rOpBypCoVlvMes.CoVlv_rOpBypCoVlvMes
          dr_WaTEst_tMtlEngEstim: data-element=R_WaTEst_tMtlEngEstim.WaTEst_tMtlEngEstim
          dr_Ext_tUcapMes: data-element=R_Ext_tUcapMes.Ext_tUcapMes
          dr_ShdFlap_stPosn: data-element=R_ShdFlap_stPosn.ShdFlap_stPosn
          dr_Ext_tECUMes: data-element=R_Ext_tECUMes.Ext_tECUMes
          dr_Ext_tOilMes: data-element=R_Ext_tOilMes.Ext_tOilMes
          dr_CoVlv_rOpRadCoVlvMes: data-element=R_CoVlv_rOpRadCoVlvMes.CoVlv_rOpRadCoVlvMes
          dr_PhyM_tTrbCaseEstim: data-element=R_PhyM_tTrbCaseEstim.PhyM_tTrbCaseEstim
          dr_Ext_tAirExtMes: data-element=R_Ext_tAirExtMes.Ext_tAirExtMes
          dr_ShwRm_bAcvFSF: data-element=R_ShwRm_bAcvFSF.ShwRm_bAcvFSF
          dr_Ext_tAirUsCmprMes: data-element=R_Ext_tAirUsCmprMes.Ext_tAirUsCmprMes
          dr_ElSysCo_bOpFSFReq: data-element=R_ElSysCo_bOpFSFReq.ElSysCo_bOpFSFReq
          dr_Ext_tOilGBx: data-element=R_Ext_tOilGBx.Ext_tOilGBx
          dr_TqCmp_bOpFSFReq_tAir: data-element=R_TqCmp_bOpFSFReq_tAir.TqCmp_bOpFSFReq_tAir
          dr_ExM_tExMnfEstim: data-element=R_ExM_tExMnfEstim.ExM_tExMnfEstim
          dr_ThMgt_wThFil: data-element=R_ThMgt_wThFil.ThMgt_wThFil
          dr_Veh_bHeatWaPmpReq: data-element=R_Veh_bHeatWaPmpReq.Veh_bHeatWaPmpReq
          dr_Ext_tBattMes: data-element=R_Ext_tBattMes.Ext_tBattMes
          dr_RvAltMgt_tRvAltStatEstim: data-element=R_RvAltMgt_tRvAltStatEstim.RvAltMgt_tRvAltStatEstim
          dr_Ext_bRawMainWaPmpSt: data-element=R_Ext_bRawMainWaPmpSt.Ext_bRawMainWaPmpSt
          dr_Stg_tSysStrWhl: data-element=R_Stg_tSysStrWhl.Stg_tSysStrWhl
          dr_Ext_tCoMes: data-element=R_Ext_tCoMes.Ext_tCoMes
          dr_Ext_tFuMes: data-element=R_Ext_tFuMes.Ext_tFuMes
          dr_Veh_bHeatReq: data-element=R_Veh_bHeatReq.Veh_bHeatReq
          dr_InThM_tAirUsInVlvEstim: data-element=R_InThM_tAirUsInVlvEstim.InThM_tAirUsInVlvEstim
        35 x data send point:
          ds_ThMgt_bTCoWarnReq: data-element=P_ThMgt_bTCoWarnReq.ThMgt_bTCoWarnReq
          ds_ThMgt_bBattFanReq: data-element=P_ThMgt_bBattFanReq.ThMgt_bBattFanReq
          ds_ThMgt_tiAcvTrbWaPmpEngStop: data-element=P_ThMgt_tiAcvTrbWaPmpEngStop.ThMgt_tiAcvTrbWaPmpEngStop
          ds_ThMgt_bPwrHldCoVlvReq: data-element=P_ThMgt_bPwrHldCoVlvReq.ThMgt_bPwrHldCoVlvReq
          ds_ThMgt_rOpHeatCoVlvReq: data-element=P_ThMgt_rOpHeatCoVlvReq.ThMgt_rOpHeatCoVlvReq
          ds_ThMgt_bAdFanReq: data-element=P_ThMgt_bAdFanReq.ThMgt_bAdFanReq
          ds_ThMgt_stPosnCoVlvEstim: data-element=P_ThMgt_stPosnCoVlvEstim.ThMgt_stPosnCoVlvEstim
          ds_ThMgt_bTrbWaPmpReq: data-element=P_ThMgt_bTrbWaPmpReq.ThMgt_bTrbWaPmpReq
          ds_ThMgt_bECUFanReq: data-element=P_ThMgt_bECUFanReq.ThMgt_bECUFanReq
          ds_ThMgt_bEndCtlCoVlv: data-element=P_ThMgt_bEndCtlCoVlv.ThMgt_bEndCtlCoVlv
          ds_ThMgt_rOpBypCoVlvReq: data-element=P_ThMgt_rOpBypCoVlvReq.ThMgt_rOpBypCoVlvReq
          ds_ThMgt_nTarIdlHeatReq: data-element=P_ThMgt_nTarIdlHeatReq.ThMgt_nTarIdlHeatReq
          ds_ThMgt_bEHRHeatReq: data-element=P_ThMgt_bEHRHeatReq.ThMgt_bEHRHeatReq
          ds_ThMgt_rCoHeatReq: data-element=P_ThMgt_rCoHeatReq.ThMgt_rCoHeatReq
          ds_ThMgt_bPwrHldAdFanReq: data-element=P_ThMgt_bPwrHldAdFanReq.ThMgt_bPwrHldAdFanReq
          ds_ThMgt_bPwrHldTrbWaPmpReq: data-element=P_ThMgt_bPwrHldTrbWaPmpReq.ThMgt_bPwrHldTrbWaPmpReq
          ds_ThMgt_bPosnFSF: data-element=P_ThMgt_bPosnFSF.ThMgt_bPosnFSF
          ds_ThMgt_bMainWaPmpReq: data-element=P_ThMgt_bMainWaPmpReq.ThMgt_bMainWaPmpReq
          ds_ThMgt_stPosnFSFReq: data-element=P_ThMgt_stPosnFSFReq.ThMgt_stPosnFSFReq
          ds_ThMgt_stSpdCoVlvReq: data-element=P_ThMgt_stSpdCoVlvReq.ThMgt_stSpdCoVlvReq
          ds_ThMgt_bPwrHldMainFanReq: data-element=P_ThMgt_bPwrHldMainFanReq.ThMgt_bPwrHldMainFanReq
          ds_ThMgt_tECTReq: data-element=P_ThMgt_tECTReq.ThMgt_tECTReq
          ds_ThMgt_bIncVoltReq: data-element=P_ThMgt_bIncVoltReq.ThMgt_bIncVoltReq
          ds_ThMgt_bMainWaPmpSt: data-element=P_ThMgt_bMainWaPmpSt.ThMgt_bMainWaPmpSt
          ds_ThMgt_bECTAftsReq: data-element=P_ThMgt_bECTAftsReq.ThMgt_bECTAftsReq
          ds_ThMgt_bEHRWaPmpReq: data-element=P_ThMgt_bEHRWaPmpReq.ThMgt_bEHRWaPmpReq
          ds_ThMgt_bHeatWaPmpReq: data-element=P_ThMgt_bHeatWaPmpReq.ThMgt_bHeatWaPmpReq
          ds_ThMgt_rPwrECTReq: data-element=P_ThMgt_rPwrECTReq.ThMgt_rPwrECTReq
          ds_ThMgt_bACCmprOffReq: data-element=P_ThMgt_bACCmprOffReq.ThMgt_bACCmprOffReq
          ds_ThMgt_rSpdFanReq: data-element=P_ThMgt_rSpdFanReq.ThMgt_rSpdFanReq
          ds_ThMgt_bAcvR1234Mgt: data-element=P_ThMgt_bAcvR1234Mgt.ThMgt_bAcvR1234Mgt
          ds_ThMgt_bRstrtReq: data-element=P_ThMgt_bRstrtReq.ThMgt_bRstrtReq
          ds_ThMgt_bHldPosnCoVlvReq: data-element=P_ThMgt_bHldPosnCoVlvReq.ThMgt_bHldPosnCoVlvReq
          ds_ThMgt_bPwrHldFSFReq: data-element=P_ThMgt_bPwrHldFSFReq.ThMgt_bPwrHldFSFReq
          ds_ThMgt_rOpRadCoVlvReq: data-element=P_ThMgt_rOpRadCoVlvReq.ThMgt_rOpRadCoVlvReq
        51 x sync call:
          ssp_FRM_bInhHeatWaPmp: operation=R_FRM_bInhHeatWaPmp.GetFunctionPermission
          ssp_FRM_bAcvBoilLimChg: operation=R_FRM_bAcvBoilLimChg.GetFunctionPermission
          ssp_FRM_bInhTCoColdDiag: operation=R_FRM_bInhTCoColdDiag.GetFunctionPermission
          ssp_FRM_bAcvEHRPmp: operation=R_FRM_bAcvEHRPmp.GetFunctionPermission
          ssp_FRM_bInhEHRPmp: operation=R_FRM_bInhEHRPmp.GetFunctionPermission
          ssp_FRM_bInhCTICoHeat: operation=R_FRM_bInhCTICoHeat.GetFunctionPermission
          ssp_FRM_bDiMoveFSFReq: operation=R_FRM_bDiMoveFSFReq.GetFunctionPermission
          ssp_ThMgt_FSFBlockCls: operation=R_ThMgt_FSFBlockCls.SetEventStatus
          ssp_FRM_bAcvCoVlvOpByp: operation=R_FRM_bAcvCoVlvOpByp.GetFunctionPermission
          ssp_FRM_bInhTCoBlockDiag: operation=R_FRM_bInhTCoBlockDiag.GetFunctionPermission
          ssp_FRM_bInhHeatReqMainWaPmp: operation=R_FRM_bInhHeatReqMainWaPmp.GetFunctionPermission
          ssp_FRM_bAcvECUFan: operation=R_FRM_bAcvECUFan.GetFunctionPermission
          ssp_FRM_bAcvAdFan: operation=R_FRM_bAcvAdFan.GetFunctionPermission
          ssp_FRM_bAcvThMgtRcvValTUsPFlt: operation=R_FRM_bAcvThMgtRcvValTUsPFlt.GetFunctionPermission
          ssp_ThMgt_FSFBlockOp: operation=R_ThMgt_FSFBlockOp.SetEventStatus
          ssp_FRM_bAcvThMgtRcvValTAirExt: operation=R_FRM_bAcvThMgtRcvValTAirExt.GetFunctionPermission
          ssp_FRM_bInhThermoDiag1: operation=R_FRM_bInhThermoDiag1.GetFunctionPermission
          ssp_FRM_bAcvCoVlvMaxOp: operation=R_FRM_bAcvCoVlvMaxOp.GetFunctionPermission
          ssp_FRM_bDeacCoVlv: operation=R_FRM_bDeacCoVlv.GetFunctionPermission
          ssp_FRM_bAcvFanHiSpdRcvMod: operation=R_FRM_bAcvFanHiSpdRcvMod.GetFunctionPermission
          ssp_FRM_bInhECTPwrLim: operation=R_FRM_bInhECTPwrLim.GetFunctionPermission
          ssp_FRM_bAcvLoTCoReg: operation=R_FRM_bAcvLoTCoReg.GetFunctionPermission
          ssp_FRM_bInhIdlIncCoHeat: operation=R_FRM_bInhIdlIncCoHeat.GetFunctionPermission
          ssp_ThMgt_TCoSlowRise: operation=R_ThMgt_TCoSlowRise.SetEventStatus
          ssp_FRM_bAcvVeryLoTCoReg: operation=R_FRM_bAcvVeryLoTCoReg.GetFunctionPermission
          ssp_FRM_bAcvCoVlvOpRad: operation=R_FRM_bAcvCoVlvOpRad.GetFunctionPermission
          ssp_FRM_bAcvFanLoSpd: operation=R_FRM_bAcvFanLoSpd.GetFunctionPermission
          ssp_FRM_bAcvTCoWarn: operation=R_FRM_bAcvTCoWarn.GetFunctionPermission
          ssp_ThMgt_ThermoStuckOp: operation=R_ThMgt_ThermoStuckOp.SetEventStatus
          ssp_FRM_bAcvCoVlvOpHeat: operation=R_FRM_bAcvCoVlvOpHeat.GetFunctionPermission
          ssp_FRM_bAcvThMgtRcvValTAirIn: operation=R_FRM_bAcvThMgtRcvValTAirIn.GetFunctionPermission
          ssp_FRM_bAcvBattFan: operation=R_FRM_bAcvBattFan.GetFunctionPermission
          ssp_FRM_bInhDiagCoBoilLim: operation=R_FRM_bInhDiagCoBoilLim.GetFunctionPermission
          ssp_FRM_bAcvHeatWaPmp: operation=R_FRM_bAcvHeatWaPmp.GetFunctionPermission
          ssp_FRM_bAcvThMgtRcvValTCAC: operation=R_FRM_bAcvThMgtRcvValTCAC.GetFunctionPermission
          ssp_FRM_bAcvLoThdACCmprOff: operation=R_FRM_bAcvLoThdACCmprOff.GetFunctionPermission
          ssp_FRM_bDeacCoBoilLim: operation=R_FRM_bDeacCoBoilLim.GetFunctionPermission
          ssp_FRM_bInhDiagFctFSF: operation=R_FRM_bInhDiagFctFSF.GetFunctionPermission
          ssp_FRM_bInhDiagTCoWarn: operation=R_FRM_bInhDiagTCoWarn.GetFunctionPermission
          ssp_ThMgt_ThermoStuckCls: operation=R_ThMgt_ThermoStuckCls.SetEventStatus
          ssp_FRM_bAcvLoThdTCoWarn: operation=R_FRM_bAcvLoThdTCoWarn.GetFunctionPermission
          ssp_ThMgt_CoSysDfct: operation=R_ThMgt_CoSysDfct.SetEventStatus
          ssp_FRM_bAcvFanHiSpd: operation=R_FRM_bAcvFanHiSpd.GetFunctionPermission
          ssp_FRM_bAcvThMgtRcvModTAlt: operation=R_FRM_bAcvThMgtRcvModTAlt.GetFunctionPermission
          ssp_ThMgt_TCoBlock: operation=R_ThMgt_TCoBlock.SetEventStatus
          ssp_FRM_bAcvThMgtRcvValTEg: operation=R_FRM_bAcvThMgtRcvValTEg.GetFunctionPermission
          ssp_FRM_bAcvOpFSF: operation=R_FRM_bAcvOpFSF.GetFunctionPermission
          ssp_FRM_bInhTCoRiseDiag: operation=R_FRM_bInhTCoRiseDiag.GetFunctionPermission
          ssp_FRM_bAcvThMgtRcvModTECU: operation=R_FRM_bAcvThMgtRcvModTECU.GetFunctionPermission
          ssp_FRM_bInhTCoMdlCompDiag: operation=R_FRM_bInhTCoMdlCompDiag.GetFunctionPermission
          ssp_ThMgt_TCoWarn: operation=R_ThMgt_TCoWarn.SetEventStatus
      RE_ThMgt_AftsNvramWrite_1
  swc implementation Imp_ThMgt: programming-language=C, behavior=IB_ThMgt
    code-descriptors:
      code CodeDescriptor: type=SRC
        20 x xfile:
          ThMgt_Lib_c: url=ThMgt_Lib.c
          ThMgt_MemMap_h: url=ThMgt_MemMap.h
          ThMgt_002_calibrations_h: url=ThMgt_002_calibrations.h
          ThMgt_Lib_h: url=ThMgt_Lib.h
          ThMgt_002_TEV_fct_c: url=ThMgt_002_TEV_fct.c
          ThMgt_002_TEV_fct_h: url=ThMgt_002_TEV_fct.h
          ThMgt_afts_c: url=ThMgt_afts.c
          ThMgt_nvm_c: url=ThMgt_nvm.c
          ThMgt_003_calibrations_h: url=ThMgt_003_calibrations.h
          ThMgt_nvm_h: url=ThMgt_nvm.h
          ThMgt_c: url=ThMgt.c
          ThMgt_004_calibrations_c: url=ThMgt_004_calibrations.c
          ThMgt_h: url=ThMgt.h
          ThMgt_002_calibrations_c: url=ThMgt_002_calibrations.c
          ThMgt_003_TEV_fct_h: url=ThMgt_003_TEV_fct.h
          ThMgt_004_TEV_fct_c: url=ThMgt_004_TEV_fct.c
          ThMgt_004_calibrations_h: url=ThMgt_004_calibrations.h
          ThMgt_003_TEV_fct_c: url=ThMgt_003_TEV_fct.c
          ThMgt_004_TEV_fct_h: url=ThMgt_004_TEV_fct.h
          ThMgt_003_calibrations_c: url=ThMgt_003_calibrations.c
package /Components/SWC_ThMgt/ThMgt_IRVDatatypes
  29 x boolean type, all with base-type=boolean:
    DT_AntiBoil_bRatCorPwrFilIniDly
    DT_AtyModMgt_bLoTCoRegReq
    DT_CoPtByp_bTqTx
    DT_CoVlvCtl_bRstStopHldDly
    DT_EGRCo_bOpCoVlvReq
    DT_ESLimByp_bAcvTrqLim
    DT_ExtByp_bFSFCf
    DT_ExtByp_bKeyOff
    DT_FRMByp_bAcvBoilLimChg
    DT_FRMByp_bAcvLoTCoReg
    DT_FRMByp_bAcvNoEgdGearDft
    DT_FRMByp_bAcvTrbWaPmp
    DT_FRMByp_bAcvVeryLoTCoReg
    DT_FRMByp_bDeacCoBoilLim
    DT_FRMByp_bInhDiagCoBoilLim
    DT_FRMByp_bInhTCoColdDiag
    DT_IgSysByp_bAcvLoTCoRegKnk
    DT_InpClc_bACCf
    DT_InpClc_bEngRun
    DT_InpClc_bEngStop
    DT_InpClc_bPFltRgnReq
    DT_InpClc_bPwtRun
    DT_OilDilProt_bLoTCoRegReq
    DT_PFltByp_bPFltRgnSrvReq
    DT_TPMByp_bExThermoProt
    DT_TRegClc_bEngWrm
    DT_TRegClc_bHiEngLd
    DT_TRegClc_bModRegCoVlv
    DT_UndHoTMgt_bLoTCoRegReq
  66 x integer type:
    DT_AirSysByp_rOpEGRCoBypReq: base-type=uint16, lower-limit=0, upper-limit=65535
    DT_AntiBoil_rCorPwrFil: base-type=uint16, lower-limit=0, upper-limit=65535
    DT_AntiBoil_tCoMesFil: base-type=int16, lower-limit=-32768, upper-limit=32767
    DT_AntiBoil_tECTReqDly: base-type=int16, lower-limit=-32768, upper-limit=32767
    DT_AtyModMgt_tECTReq: base-type=int16, lower-limit=-32768, upper-limit=32767
    DT_CmptFil_agStrWhlFil: base-type=int16, lower-limit=-32768, upper-limit=32767
    DT_CmptFil_agvStrWhlFil: base-type=uint16, lower-limit=0, upper-limit=65535
    DT_CmptFil_tCACFil: base-type=int16, lower-limit=-32768, upper-limit=32767
    DT_CoAftsMgt_tECTAftsReq: base-type=int16, lower-limit=-32768, upper-limit=32767
    DT_CoPtByp_noEgdGearCord: base-type=uint8, lower-limit=0, upper-limit=255
    DT_CoPtByp_stCpl: base-type=uint8, lower-limit=0, upper-limit=255
    DT_EGRCo_stSpdCoVlvReq: base-type=uint8, lower-limit=0, upper-limit=255
    DT_EGRVlvByp_rOp: base-type=uint16, lower-limit=0, upper-limit=65535
    DT_EngLimByp_tqIdcEngCur: base-type=uint16, lower-limit=0, upper-limit=65535
    DT_EngMByp_mfDsEGRCoEstim: base-type=uint16, lower-limit=0, upper-limit=65535
    DT_EngMByp_mfEgEstim: base-type=uint16, lower-limit=0, upper-limit=65535
    DT_EOMByp_stCmbTdOff: base-type=uint8, lower-limit=0, upper-limit=255
    DT_EOMByp_tiEngStop: base-type=uint32, lower-limit=0, upper-limit=4294967295
    DT_ExtByp_nEng: base-type=uint16, lower-limit=0, upper-limit=65535
    DT_ExtByp_pAirExtMes: base-type=uint16, lower-limit=0, upper-limit=65535
    DT_ExtByp_spdVeh: base-type=uint8, lower-limit=0, upper-limit=255
    DT_ExtByp_stGBxCf: base-type=uint8, lower-limit=0, upper-limit=255
    DT_ExtByp_stVSSCf: base-type=uint8, lower-limit=0, upper-limit=255
    DT_ExtByp_tAirExtMes: base-type=int16, lower-limit=-32768, upper-limit=32767
    DT_ExtByp_tAirUsCmprMes: base-type=int16, lower-limit=-32768, upper-limit=32767
    DT_ExtByp_tCoMes: base-type=int16, lower-limit=-32768, upper-limit=32767
    DT_ExtByp_tCoMesFineResl2: base-type=int16, lower-limit=-32768, upper-limit=32767
    DT_ExtByp_tDsThrMes: base-type=int16, lower-limit=-32768, upper-limit=32767
    DT_ExtByp_tECTSp: base-type=int16, lower-limit=-32768, upper-limit=32767
    DT_ExtByp_tFuMes: base-type=int16, lower-limit=-32768, upper-limit=32767
    DT_ExtByp_tOilMes: base-type=int16, lower-limit=-32768, upper-limit=32767
    DT_ExtByp_tUsPFlt: base-type=int16, lower-limit=-32768, upper-limit=32767
    DT_ExtByp_tUsThrMes: base-type=int16, lower-limit=-32768, upper-limit=32767
    DT_GBxCo_tECTReqDly: base-type=int16, lower-limit=-32768, upper-limit=32767
    DT_InpClc_tAirInMes: base-type=int16, lower-limit=-32768, upper-limit=32767
    DT_InpClc_tCAC: base-type=int16, lower-limit=-32768, upper-limit=32767
    DT_InpClc_tEg: base-type=int16, lower-limit=-32768, upper-limit=32767
    DT_InpClc_tqIdcEstim: base-type=uint16, lower-limit=0, upper-limit=65535
    DT_InpClc_tqIdcFld: base-type=uint16, lower-limit=0, upper-limit=65535
    DT_InThMByp_tAirUsInVlvEstim: base-type=int16, lower-limit=-32768, upper-limit=32767
    DT_KnkMgtByp_ctRblInjCutOffPtl: base-type=uint8, lower-limit=0, upper-limit=255
    DT_KnkProt_tECTAdpReq: base-type=int16, lower-limit=-32768, upper-limit=32767
    DT_KnkProt_tECTTAirReq: base-type=int16, lower-limit=-32768, upper-limit=32767
    DT_OAMByp_rOilDil: base-type=uint16, lower-limit=0, upper-limit=65535
    DT_PwtFil_nEngFil: base-type=uint16, lower-limit=0, upper-limit=65535
    DT_PwtFil_tCoRegFil{1..3}: base-type=int16, lower-limit=-32768, upper-limit=32767
    DT_PwtFil_tqIdcEstimFil: base-type=int16, lower-limit=-32768, upper-limit=32767
    DT_StgByp_agStrWhl: base-type=int16, lower-limit=-32768, upper-limit=32767
    DT_StgByp_agvStrWhl: base-type=uint16, lower-limit=0, upper-limit=65535
    DT_ThEClc_wThFil2: base-type=uint16, lower-limit=0, upper-limit=65535
    DT_TqSysByp_tqIdcAirReqGen: base-type=uint16, lower-limit=0, upper-limit=65535
    DT_TRegClc_tCoRegCoVlv: base-type=int16, lower-limit=-32768, upper-limit=32767
    DT_TRegClc_tCoRegECT: base-type=int16, lower-limit=-32768, upper-limit=32767
    DT_UndHoFil_nEngFil1: base-type=uint16, lower-limit=0, upper-limit=65535
    DT_UndHoFil_nEngFil2: base-type=uint16, lower-limit=0, upper-limit=65535
    DT_UndHoFil_spdVehFil1: base-type=uint8, lower-limit=0, upper-limit=255
    DT_UndHoFil_spdVehFil2: base-type=uint8, lower-limit=0, upper-limit=255
    DT_UndHoFil_tAirExtMesFil1: base-type=int16, lower-limit=-32768, upper-limit=32767
    DT_UndHoFil_tAirExtMesFil2: base-type=int16, lower-limit=-32768, upper-limit=32767
    DT_UndHoFil_tAirInMesFil: base-type=int16, lower-limit=-32768, upper-limit=32767
    DT_UndHoFil_tqIdcEstimFil1: base-type=int16, lower-limit=-32768, upper-limit=32767
    DT_UndHoFil_tqIdcEstimFil2: base-type=int16, lower-limit=-32768, upper-limit=32767
    DT_UndHoFil_tUsPFltFil: base-type=int16, lower-limit=-32768, upper-limit=32767
    DT_UndHoTMgt_tECTReq: base-type=int16, lower-limit=-32768, upper-limit=32767
